VERSION ""

NS_ :

BS_:
BU_: ME SC01 BMS01 BMS PT
BO_ 113 BMS05_DriveLimits: 8 BMS05
 SG_ dchgCurrentLimit_BMS05 : 55|16@0+ (0.05,0) [0|3200] "A"  BMS
 SG_ regenCurrentLimit_BMS05 : 39|16@0+ (0.05,0) [0|3200] "A"  BMS
 SG_ minStringVLimit_BMS05 : 23|16@0+ (0.02,0) [0|1200] "V"  BMS
 SG_ maxStringVLimit_BMS05 : 7|16@0+ (0.02,0) [0|1200] "V"  BMS

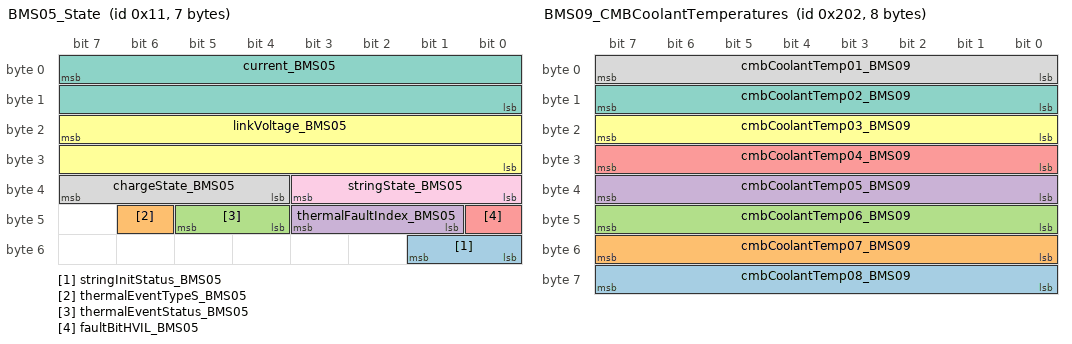
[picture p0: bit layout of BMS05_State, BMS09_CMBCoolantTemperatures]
BO_ 17 BMS05_State: 7 BMS05
 SG_ stringInitStatus_BMS05 : 49|2@0+ (1,0) [0|3] ""  BMS
 SG_ thermalEventTypeS_BMS05 : 46|1@0+ (1,0) [0|1] ""  BMS
 SG_ thermalEventStatus_BMS05 : 45|2@0+ (1,0) [0|2550] ""  BMS
 SG_ thermalFaultIndex_BMS05 : 43|3@0+ (1,0) [0|7] ""  BMS
 SG_ faultBitHVIL_BMS05 : 40|1@0+ (1,0) [0|1] ""  BMS
 SG_ linkVoltage_BMS05 : 23|16@0+ (0.02,0) [0|1200] "V"  BMS
 SG_ current_BMS05 : 7|16@0+ (0.1,-3200) [-3200|3353.5] "A"  BMS
 SG_ chargeState_BMS05 : 39|4@0+ (1,0) [0|15] ""  BMS
 SG_ stringState_BMS05 : 35|4@0+ (1,0) [0|0] ""  BMS

BO_ 402 BMS09_SlowDataMpex: 8 BMS09
 SG_ SW_VersionBL_BMS09 m4 : 15|32@0+ (1,0) [0|4294967295] ""  BMS
 SG_ SW_Version_BMS09 m3 : 15|32@0+ (1,0) [0|4294967295] ""  BMS
 SG_ PackSerialNumber_char20_BMS09 m2 : 55|8@0+ (1,0) [0|255] ""  BMS
 SG_ PackSerialNumber_char19_BMS09 m2 : 47|8@0+ (1,0) [0|255] ""  BMS
 SG_ PackSerialNumber_char18_BMS09 m2 : 39|8@0+ (1,0) [0|255] ""  BMS
 SG_ PackSerialNumber_char17_BMS09 m2 : 31|8@0+ (1,0) [0|255] ""  BMS
 SG_ PackSerialNumber_char16_BMS09 m2 : 23|8@0+ (1,0) [0|255] ""  BMS
 SG_ PackSerialNumber_char15_BMS09 m2 : 15|8@0+ (1,0) [0|255] ""  BMS
 SG_ PackSerialNumber_char14_BMS09 m1 : 63|8@0+ (1,0) [0|255] ""  BMS
 SG_ PackSerialNumber_char13_BMS09 m1 : 55|8@0+ (1,0) [0|255] ""  BMS
 SG_ PackSerialNumber_char12_BMS09 m1 : 47|8@0+ (1,0) [0|255] ""  BMS
 SG_ PackSerialNumber_char11_BMS09 m1 : 39|8@0+ (1,0) [0|255] ""  BMS
 SG_ PackSerialNumber_char10_BMS09 m1 : 31|8@0+ (1,0) [0|255] ""  BMS
 SG_ PackSerialNumber_char08_BMS09 m1 : 15|8@0+ (1,0) [0|255] ""  BMS
 SG_ PackSerialNumber_char09_BMS09 m1 : 23|8@0+ (1,0) [0|255] ""  BMS
 SG_ SlowDataMpx_BMS09 M : 7|8@0+ (1,0) [0|255] ""  BMS
 SG_ PackSerialNumber_char07_BMS09 m0 : 63|8@0+ (1,0) [0|255] ""  BMS
 SG_ PackSerialNumber_char06_BMS09 m0 : 55|8@0+ (1,0) [0|255] ""  BMS
 SG_ PackSerialNumber_char05_BMS09 m0 : 47|8@0+ (1,0) [0|255] ""  BMS
 SG_ PackSerialNumber_char04_BMS09 m0 : 39|8@0+ (1,0) [0|255] ""  BMS
 SG_ PackSerialNumber_char03_BMS09 m0 : 31|8@0+ (1,0) [0|255] ""  BMS
 SG_ PackSerialNumber_char02_BMS09 m0 : 23|8@0+ (1,0) [0|255] ""  BMS
 SG_ PackSerialNumber_char01_BMS09 m0 : 15|8@0+ (1,0) [0|255] ""  BMS

BO_ 530 BMS09_CoolantTemperatures: 8 BMS
 SG_ coolantOutletTemperature_BMS09 : 15|8@0+ (1,-40) [-40|215] "C"  BMS
 SG_ coolantInletTemperature_BMS09 : 7|8@0+ (1,-40) [-40|215] "C"  BMS

BO_ 514 BMS09_CMBCoolantTemperatures: 8 BMS
 SG_ cmbCoolantTemp08_BMS09 : 63|8@0+ (1,-40) [-40|200] "C"  BMS
 SG_ cmbCoolantTemp07_BMS09 : 55|8@0+ (1,-40) [-40|200] "C"  BMS
 SG_ cmbCoolantTemp06_BMS09 : 47|8@0+ (1,-40) [-40|200] "C"  BMS
 SG_ cmbCoolantTemp05_BMS09 : 39|8@0+ (1,-40) [-40|200] "C"  BMS
 SG_ cmbCoolantTemp04_BMS09 : 31|8@0+ (1,-40) [-40|200] "C"  BMS
 SG_ cmbCoolantTemp03_BMS09 : 23|8@0+ (1,-40) [-40|200] "C"  BMS
 SG_ cmbCoolantTemp02_BMS09 : 15|8@0+ (1,-40) [-40|200] "C"  BMS
 SG_ cmbCoolantTemp01_BMS09 : 7|8@0+ (1,-40) [-40|200] "C"  BMS

BO_ 386 BMS09_EnergyThroughput: 5 BMS09
 SG_ maxFluidPressureInlet_BMS09 : 39|8@0+ (10,0) [0|2550] "mbar"  BMS
 SG_ energyThroughput_KWh_BMS09 : 7|32@0+ (0.01,0) [0|42949672.95] "KWh"  BMS

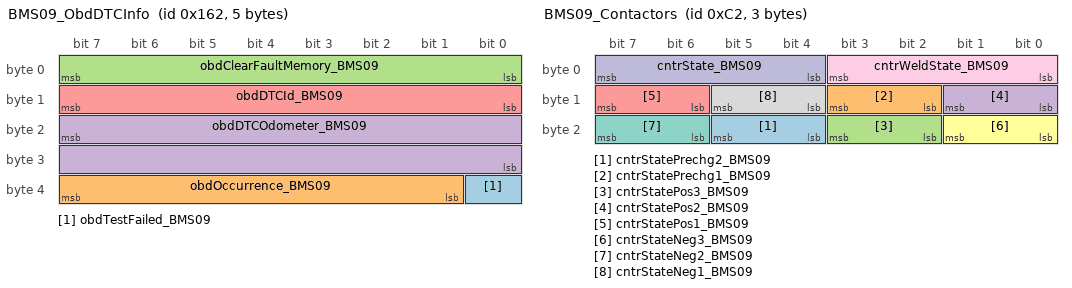
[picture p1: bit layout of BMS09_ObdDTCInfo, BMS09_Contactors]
BO_ 354 BMS09_ObdDTCInfo: 5 BMS09
 SG_ obdTestFailed_BMS09 : 32|1@0+ (1,0) [0|1] ""  BMS
 SG_ obdOccurrence_BMS09 : 39|7@0+ (1,0) [0|126] ""  BMS
 SG_ obdClearFaultMemory_BMS09 : 7|8@0+ (1,0) [0|1] ""  BMS
 SG_ obdDTCOdometer_BMS09 : 23|16@0+ (1,0) [0|65535] "km"  BMS
 SG_ obdDTCId_BMS09 : 15|8@0+ (1,0) [0|255] ""  BMS

BO_ 338 BMS09_SOCIndeces: 4 BMS09
 SG_ maxSOCIndex_BMS09 : 23|16@0+ (1,0) [0|65535] ""  BMS
 SG_ minSOCIndex_BMS09 : 7|16@0+ (1,0) [0|65535] ""  BMS

BO_ 322 BMS09_Charge: 8 BMS09
 SG_ cusDschrgEnrgyLifeTime_BMS09 : 55|16@0+ (0.1,0) [0|1310.7] "MWh"  BMS
 SG_ cusChrgEnrgyLifeTime_BMS09 : 39|16@0+ (0.1,0) [0|1310.7] "MWh"  BMS
 SG_ chargeEnergyAvailable_BMS09 : 7|16@0+ (0.01,0) [0|0] "kWh"  BMS

BO_ 210 BMS09_StringShutdown: 3 BMS09
 SG_ stringShutdownTarget_BMS09 : 19|4@0+ (1,0) [0|0] ""  BMS
 SG_ stringShutdownTimer_BMS09 : 7|16@0+ (1,0) [0|0] ""  BMS

BO_ 194 BMS09_Contactors: 3 BMS09
 SG_ cntrStatePrechg2_BMS09 : 21|2@0+ (1,0) [0|0] ""  BMS
 SG_ cntrStatePrechg1_BMS09 : 11|2@0+ (1,0) [0|0] ""  BMS
 SG_ cntrStatePos3_BMS09 : 19|2@0+ (1,0) [0|0] ""  BMS
 SG_ cntrStatePos2_BMS09 : 9|2@0+ (1,0) [0|0] ""  BMS
 SG_ cntrStatePos1_BMS09 : 15|2@0+ (1,0) [0|0] ""  BMS
 SG_ cntrStateNeg3_BMS09 : 17|2@0+ (1,0) [0|0] ""  BMS
 SG_ cntrStateNeg2_BMS09 : 23|2@0+ (1,0) [0|0] ""  BMS
 SG_ cntrStateNeg1_BMS09 : 13|2@0+ (1,0) [0|0] ""  BMS
 SG_ cntrWeldState_BMS09 : 3|4@0+ (1,0) [0|0] ""  BMS
 SG_ cntrState_BMS09 : 7|4@0+ (1,0) [0|0] ""  BMS

BO_ 162 BMS09_PowerPrediction: 8 BMS09
 SG_ regenPowerPredShrt_BMS09 : 39|16@0+ (0.01,0) [0|650] "kW"  BMS
 SG_ regenPowerPredLong_BMS09 : 55|16@0+ (0.01,0) [0|650] "kW"  BMS
 SG_ dchgPowerPredShrt_BMS09 : 7|16@0+ (0.01,0) [0|650] "kW"  BMS
 SG_ dchgPowerPredLong_BMS09 : 23|16@0+ (0.01,0) [0|650] "kW"  BMS

BO_ 178 BMS09_CellVLimits: 8 BMS09
 SG_ cusMaxCellVLimit_BMS09 : 23|16@0+ (0.0001,0) [0|6.5] "V"  BMS
 SG_ cusMinCellVLimit_BMS09 : 7|16@0+ (0.0001,0) [0|6.5] "V"  BMS

BO_ 146 BMS09_VoltagePrediction: 8 BMS09
 SG_ dchgVoltagePredShrt_BMS09 : 7|16@0+ (0.02,0) [0|1200] "V"  BMS
 SG_ dchgVoltagePredLong_BMS09 : 23|16@0+ (0.02,0) [0|1200] "V"  BMS
 SG_ regenVoltagePredShrt_BMS09 : 39|16@0+ (0.02,0) [0|1200] "V"  BMS
 SG_ regenVoltagePredLong_BMS09 : 55|16@0+ (0.02,0) [0|1200] "V"  BMS

BO_ 130 BMS09_CurrentPrediction: 8 BMS09
 SG_ regenCurrentPredShrt_BMS09 : 39|16@0+ (0.05,0) [0|3200] "A"  BMS
 SG_ regenCurrentPredLong_BMS09 : 55|16@0+ (0.05,0) [0|3200] "A"  BMS
 SG_ dchgCurrentPredShrt_BMS09 : 7|16@0+ (0.05,0) [0|3200] "A"  BMS
 SG_ dchgCurrentPredLong_BMS09 : 23|16@0+ (0.05,0) [0|3200] "A"  BMS

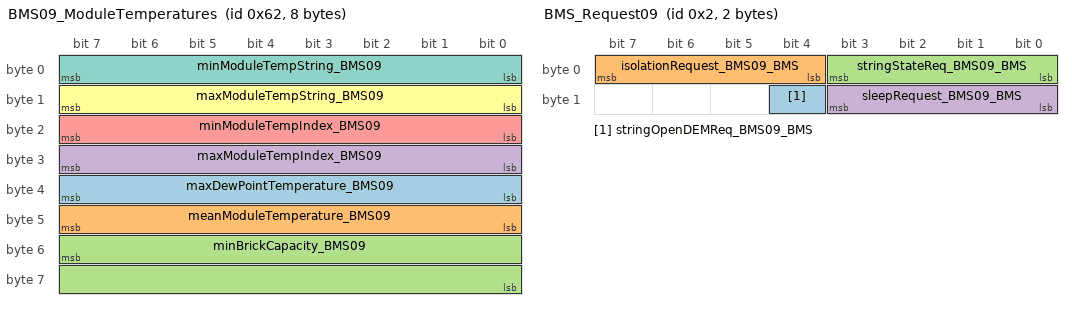
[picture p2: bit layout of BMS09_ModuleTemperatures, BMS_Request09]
BO_ 98 BMS09_ModuleTemperatures: 8 BMS09
 SG_ maxDewPointTemperature_BMS09 : 39|8@0+ (0.5,-40) [-40|87.5] "C"  BMS
 SG_ meanModuleTemperature_BMS09 : 47|8@0+ (0.5,-40) [-40|87.5] "C"  BMS
 SG_ minBrickCapacity_BMS09 : 55|16@0+ (20,0) [0|1310700] "As"  BMS
 SG_ maxModuleTempIndex_BMS09 : 31|8@0+ (1,0) [0|255] ""  BMS
 SG_ minModuleTempIndex_BMS09 : 23|8@0+ (1,0) [0|255] ""  BMS
 SG_ maxModuleTempString_BMS09 : 15|8@0+ (0.5,-40) [-40|87.5] "C"  BMS
 SG_ minModuleTempString_BMS09 : 7|8@0+ (0.5,-40) [-40|87.5] "C"  BMS

BO_ 34 BMS09_StringVoltageCharge: 8 BMS09
 SG_ brickOpenCircuitV_BMS09 : 55|16@0+ (0.0001,0) [0|6.5] "V"  BMS
 SG_ meanSOC_BMS09 : 39|16@0+ (0.01,0) [0|100] "PCT"  BMS
 SG_ stringVoltage_BMS09 : 7|16@0+ (0.02,0) [0|1200] "V"  BMS
 SG_ chargerCurrentLimit_BMS09 : 23|16@0+ (0.05,0) [0|3200] "A"  BMS

BO_ 2 BMS_Request09: 2 BMS
 SG_ stringOpenDEMReq_BMS09_BMS : 12|1@0+ (1,0) [0|0] ""  BMS
 SG_ isolationRequest_BMS09_BMS : 7|4@0+ (1,0) [0|0] ""  BMS
 SG_ stringStateReq_BMS09_BMS : 3|4@0+ (1,0) [0|0] ""  BMS
 SG_ sleepRequest_BMS09_BMS : 11|4@0+ (1,0) [0|0] ""  BMS

BO_ 82 BMS09_BrickVoltages: 8 BMS09
 SG_ maxBrickVoltageIndex_BMS09 : 55|16@0+ (1,0) [0|65535] ""  BMS
 SG_ minBrickVoltageIndex_BMS09 : 39|16@0+ (1,0) [0|65535] ""  BMS
 SG_ minBrickVoltage_BMS09 : 7|16@0+ (0.0001,0) [0|6.5] "V"  BMS
 SG_ maxBrickVoltage_BMS09 : 23|16@0+ (0.0001,0) [0|6.5] "V"  BMS

BO_ 50 BMS09_IsolationSOC: 8 BMS09
 SG_ maxSOC_BMS09 : 55|16@0+ (0.01,0) [0|100] "PCT"  BMS
 SG_ minSOC_BMS09 : 39|16@0+ (0.01,0) [0|100] "PCT"  BMS
 SG_ isolationResInternal_BMS09 : 23|16@0+ (2,0) [0|130000] "kOhm"  BMS
 SG_ isolationResExternal_BMS09 : 7|16@0+ (2,0) [0|130000] "kOhm"  BMS

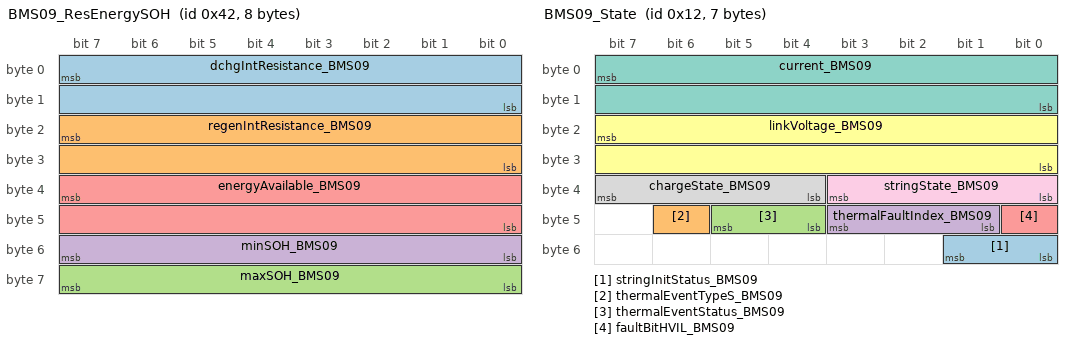
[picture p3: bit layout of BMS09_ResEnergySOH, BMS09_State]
BO_ 66 BMS09_ResEnergySOH: 8 BMS09
 SG_ dchgIntResistance_BMS09 : 7|16@0+ (0.05,0) [0|3276.75] "mOhm"  BMS
 SG_ regenIntResistance_BMS09 : 23|16@0+ (0.05,0) [0|3276.75] "mOhm"  BMS
 SG_ maxSOH_BMS09 : 63|8@0+ (0.5,0) [0|120] "PCT"  BMS
 SG_ minSOH_BMS09 : 55|8@0+ (0.5,0) [0|120] "PCT"  BMS
 SG_ energyAvailable_BMS09 : 39|16@0+ (0.01,0) [0|650] "kWh"  BMS

BO_ 114 BMS09_DriveLimits: 8 BMS09
 SG_ dchgCurrentLimit_BMS09 : 55|16@0+ (0.05,0) [0|3200] "A"  BMS
 SG_ regenCurrentLimit_BMS09 : 39|16@0+ (0.05,0) [0|3200] "A"  BMS
 SG_ minStringVLimit_BMS09 : 23|16@0+ (0.02,0) [0|1200] "V"  BMS
 SG_ maxStringVLimit_BMS09 : 7|16@0+ (0.02,0) [0|1200] "V"  BMS

BO_ 18 BMS09_State: 7 BMS09
 SG_ stringInitStatus_BMS09 : 49|2@0+ (1,0) [0|3] ""  BMS
 SG_ thermalEventTypeS_BMS09 : 46|1@0+ (1,0) [0|1] ""  BMS
 SG_ thermalEventStatus_BMS09 : 45|2@0+ (1,0) [0|2550] ""  BMS
 SG_ thermalFaultIndex_BMS09 : 43|3@0+ (1,0) [0|7] ""  BMS
 SG_ faultBitHVIL_BMS09 : 40|1@0+ (1,0) [0|1] ""  BMS
 SG_ linkVoltage_BMS09 : 23|16@0+ (0.02,0) [0|1200] "V"  BMS
 SG_ current_BMS09 : 7|16@0+ (0.1,-3200) [-3200|3353.5] "A"  BMS
 SG_ chargeState_BMS09 : 39|4@0+ (1,0) [0|15] ""  BMS
 SG_ stringState_BMS09 : 35|4@0+ (1,0) [0|0] ""  BMS

BO_ 403 BMS13_SlowDataMpex: 8 BMS13
 SG_ SW_VersionBL_BMS13 m4 : 15|32@0+ (1,0) [0|4294967295] ""  BMS
 SG_ SW_Version_BMS13 m3 : 15|32@0+ (1,0) [0|4294967295] ""  BMS
 SG_ PackSerialNumber_char20_BMS13 m2 : 55|8@0+ (1,0) [0|255] ""  BMS
 SG_ PackSerialNumber_char19_BMS13 m2 : 47|8@0+ (1,0) [0|255] ""  BMS
 SG_ PackSerialNumber_char18_BMS13 m2 : 39|8@0+ (1,0) [0|255] ""  BMS
 SG_ PackSerialNumber_char17_BMS13 m2 : 31|8@0+ (1,0) [0|255] ""  BMS
 SG_ PackSerialNumber_char16_BMS13 m2 : 23|8@0+ (1,0) [0|255] ""  BMS
 SG_ PackSerialNumber_char15_BMS13 m2 : 15|8@0+ (1,0) [0|255] ""  BMS
 SG_ PackSerialNumber_char14_BMS13 m1 : 63|8@0+ (1,0) [0|255] ""  BMS
 SG_ PackSerialNumber_char13_BMS13 m1 : 55|8@0+ (1,0) [0|255] ""  BMS
 SG_ PackSerialNumber_char12_BMS13 m1 : 47|8@0+ (1,0) [0|255] ""  BMS
 SG_ PackSerialNumber_char11_BMS13 m1 : 39|8@0+ (1,0) [0|255] ""  BMS
 SG_ PackSerialNumber_char10_BMS13 m1 : 31|8@0+ (1,0) [0|255] ""  BMS
 SG_ PackSerialNumber_char08_BMS13 m1 : 15|8@0+ (1,0) [0|255] ""  BMS
 SG_ PackSerialNumber_char09_BMS13 m1 : 23|8@0+ (1,0) [0|255] ""  BMS
 SG_ SlowDataMpx_BMS13 M : 7|8@0+ (1,0) [0|255] ""  BMS
 SG_ PackSerialNumber_char07_BMS13 m0 : 63|8@0+ (1,0) [0|255] ""  BMS
 SG_ PackSerialNumber_char06_BMS13 m0 : 55|8@0+ (1,0) [0|255] ""  BMS
 SG_ PackSerialNumber_char05_BMS13 m0 : 47|8@0+ (1,0) [0|255] ""  BMS
 SG_ PackSerialNumber_char04_BMS13 m0 : 39|8@0+ (1,0) [0|255] ""  BMS
 SG_ PackSerialNumber_char03_BMS13 m0 : 31|8@0+ (1,0) [0|255] ""  BMS
 SG_ PackSerialNumber_char02_BMS13 m0 : 23|8@0+ (1,0) [0|255] ""  BMS
 SG_ PackSerialNumber_char01_BMS13 m0 : 15|8@0+ (1,0) [0|255] ""  BMS

BO_ 531 BMS13_CoolantTemperatures: 8 BMS
 SG_ coolantOutletTemperature_BMS13 : 15|8@0+ (1,-40) [-40|215] "C"  BMS
 SG_ coolantInletTemperature_BMS13 : 7|8@0+ (1,-40) [-40|215] "C"  BMS

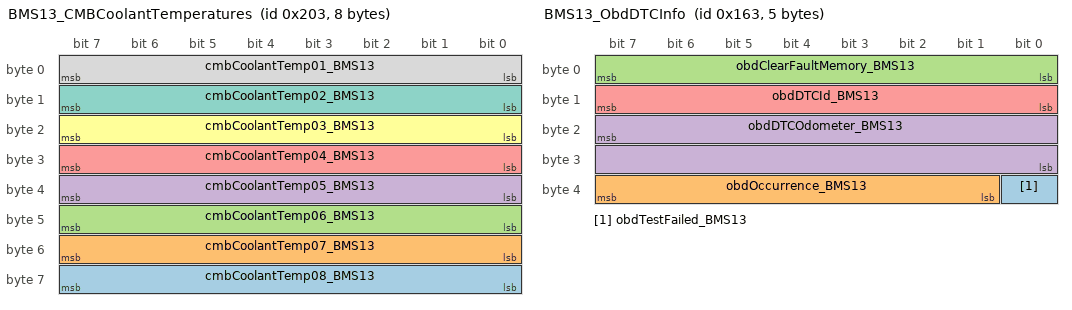
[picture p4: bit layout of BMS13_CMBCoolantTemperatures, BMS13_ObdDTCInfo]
BO_ 515 BMS13_CMBCoolantTemperatures: 8 BMS
 SG_ cmbCoolantTemp08_BMS13 : 63|8@0+ (1,-40) [-40|200] "C"  BMS
 SG_ cmbCoolantTemp07_BMS13 : 55|8@0+ (1,-40) [-40|200] "C"  BMS
 SG_ cmbCoolantTemp06_BMS13 : 47|8@0+ (1,-40) [-40|200] "C"  BMS
 SG_ cmbCoolantTemp05_BMS13 : 39|8@0+ (1,-40) [-40|200] "C"  BMS
 SG_ cmbCoolantTemp04_BMS13 : 31|8@0+ (1,-40) [-40|200] "C"  BMS
 SG_ cmbCoolantTemp03_BMS13 : 23|8@0+ (1,-40) [-40|200] "C"  BMS
 SG_ cmbCoolantTemp02_BMS13 : 15|8@0+ (1,-40) [-40|200] "C"  BMS
 SG_ cmbCoolantTemp01_BMS13 : 7|8@0+ (1,-40) [-40|200] "C"  BMS

BO_ 387 BMS13_EnergyThroughput: 5 BMS13
 SG_ maxFluidPressureInlet_BMS13 : 39|8@0+ (10,0) [0|2550] "mbar"  BMS
 SG_ energyThroughput_KWh_BMS13 : 7|32@0+ (0.01,0) [0|42949672.95] "KWh"  BMS

BO_ 355 BMS13_ObdDTCInfo: 5 BMS13
 SG_ obdTestFailed_BMS13 : 32|1@0+ (1,0) [0|1] ""  BMS
 SG_ obdOccurrence_BMS13 : 39|7@0+ (1,0) [0|126] ""  BMS
 SG_ obdClearFaultMemory_BMS13 : 7|8@0+ (1,0) [0|1] ""  BMS
 SG_ obdDTCOdometer_BMS13 : 23|16@0+ (1,0) [0|65535] "km"  BMS
 SG_ obdDTCId_BMS13 : 15|8@0+ (1,0) [0|255] ""  BMS

BO_ 339 BMS13_SOCIndeces: 4 BMS13
 SG_ maxSOCIndex_BMS13 : 23|16@0+ (1,0) [0|65535] ""  BMS
 SG_ minSOCIndex_BMS13 : 7|16@0+ (1,0) [0|65535] ""  BMS

BO_ 323 BMS13_Charge: 8 BMS13
 SG_ cusDschrgEnrgyLifeTime_BMS13 : 55|16@0+ (0.1,0) [0|1310.7] "MWh"  BMS
 SG_ cusChrgEnrgyLifeTime_BMS13 : 39|16@0+ (0.1,0) [0|1310.7] "MWh"  BMS
 SG_ chargeEnergyAvailable_BMS13 : 7|16@0+ (0.01,0) [0|0] "kWh"  BMS

BO_ 211 BMS13_StringShutdown: 3 BMS13
 SG_ stringShutdownTarget_BMS13 : 19|4@0+ (1,0) [0|0] ""  BMS
 SG_ stringShutdownTimer_BMS13 : 7|16@0+ (1,0) [0|0] ""  BMS

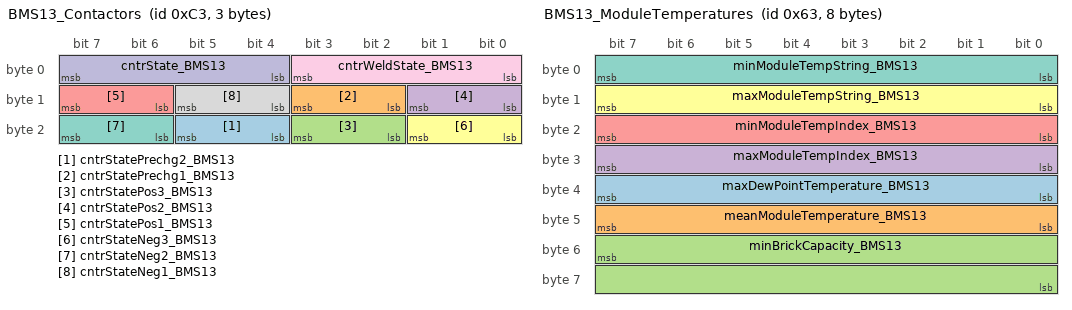
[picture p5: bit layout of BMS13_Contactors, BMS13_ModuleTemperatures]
BO_ 195 BMS13_Contactors: 3 BMS13
 SG_ cntrStatePrechg2_BMS13 : 21|2@0+ (1,0) [0|0] ""  BMS
 SG_ cntrStatePrechg1_BMS13 : 11|2@0+ (1,0) [0|0] ""  BMS
 SG_ cntrStatePos3_BMS13 : 19|2@0+ (1,0) [0|0] ""  BMS
 SG_ cntrStatePos2_BMS13 : 9|2@0+ (1,0) [0|0] ""  BMS
 SG_ cntrStatePos1_BMS13 : 15|2@0+ (1,0) [0|0] ""  BMS
 SG_ cntrStateNeg3_BMS13 : 17|2@0+ (1,0) [0|0] ""  BMS
 SG_ cntrStateNeg2_BMS13 : 23|2@0+ (1,0) [0|0] ""  BMS
 SG_ cntrStateNeg1_BMS13 : 13|2@0+ (1,0) [0|0] ""  BMS
 SG_ cntrWeldState_BMS13 : 3|4@0+ (1,0) [0|0] ""  BMS
 SG_ cntrState_BMS13 : 7|4@0+ (1,0) [0|0] ""  BMS

BO_ 163 BMS13_PowerPrediction: 8 BMS13
 SG_ regenPowerPredShrt_BMS13 : 39|16@0+ (0.01,0) [0|650] "kW"  BMS
 SG_ regenPowerPredLong_BMS13 : 55|16@0+ (0.01,0) [0|650] "kW"  BMS
 SG_ dchgPowerPredShrt_BMS13 : 7|16@0+ (0.01,0) [0|650] "kW"  BMS
 SG_ dchgPowerPredLong_BMS13 : 23|16@0+ (0.01,0) [0|650] "kW"  BMS

BO_ 179 BMS13_CellVLimits: 8 BMS13
 SG_ cusMaxCellVLimit_BMS13 : 23|16@0+ (0.0001,0) [0|6.5] "V"  BMS
 SG_ cusMinCellVLimit_BMS13 : 7|16@0+ (0.0001,0) [0|6.5] "V"  BMS

BO_ 147 BMS13_VoltagePrediction: 8 BMS13
 SG_ dchgVoltagePredShrt_BMS13 : 7|16@0+ (0.02,0) [0|1200] "V"  BMS
 SG_ dchgVoltagePredLong_BMS13 : 23|16@0+ (0.02,0) [0|1200] "V"  BMS
 SG_ regenVoltagePredShrt_BMS13 : 39|16@0+ (0.02,0) [0|1200] "V"  BMS
 SG_ regenVoltagePredLong_BMS13 : 55|16@0+ (0.02,0) [0|1200] "V"  BMS

BO_ 131 BMS13_CurrentPrediction: 8 BMS13
 SG_ regenCurrentPredShrt_BMS13 : 39|16@0+ (0.05,0) [0|3200] "A"  BMS
 SG_ regenCurrentPredLong_BMS13 : 55|16@0+ (0.05,0) [0|3200] "A"  BMS
 SG_ dchgCurrentPredShrt_BMS13 : 7|16@0+ (0.05,0) [0|3200] "A"  BMS
 SG_ dchgCurrentPredLong_BMS13 : 23|16@0+ (0.05,0) [0|3200] "A"  BMS

BO_ 99 BMS13_ModuleTemperatures: 8 BMS13
 SG_ maxDewPointTemperature_BMS13 : 39|8@0+ (0.5,-40) [-40|87.5] "C"  BMS
 SG_ meanModuleTemperature_BMS13 : 47|8@0+ (0.5,-40) [-40|87.5] "C"  BMS
 SG_ minBrickCapacity_BMS13 : 55|16@0+ (20,0) [0|1310700] "As"  BMS
 SG_ maxModuleTempIndex_BMS13 : 31|8@0+ (1,0) [0|255] ""  BMS
 SG_ minModuleTempIndex_BMS13 : 23|8@0+ (1,0) [0|255] ""  BMS
 SG_ maxModuleTempString_BMS13 : 15|8@0+ (0.5,-40) [-40|87.5] "C"  BMS
 SG_ minModuleTempString_BMS13 : 7|8@0+ (0.5,-40) [-40|87.5] "C"  BMS

BO_ 35 BMS13_StringVoltageCharge: 8 BMS13
 SG_ brickOpenCircuitV_BMS13 : 55|16@0+ (0.0001,0) [0|6.5] "V"  BMS
 SG_ meanSOC_BMS13 : 39|16@0+ (0.01,0) [0|100] "PCT"  BMS
 SG_ stringVoltage_BMS13 : 7|16@0+ (0.02,0) [0|1200] "V"  BMS
 SG_ chargerCurrentLimit_BMS13 : 23|16@0+ (0.05,0) [0|3200] "A"  BMS

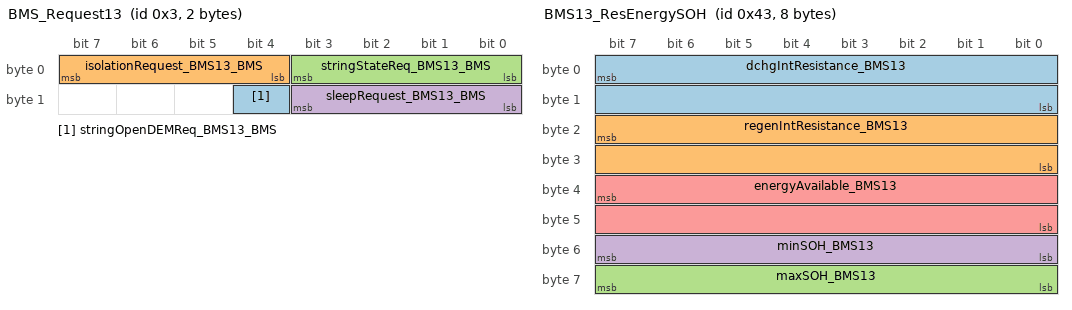
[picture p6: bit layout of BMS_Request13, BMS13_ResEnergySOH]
BO_ 3 BMS_Request13: 2 BMS
 SG_ stringOpenDEMReq_BMS13_BMS : 12|1@0+ (1,0) [0|0] ""  BMS
 SG_ isolationRequest_BMS13_BMS : 7|4@0+ (1,0) [0|0] ""  BMS
 SG_ stringStateReq_BMS13_BMS : 3|4@0+ (1,0) [0|0] ""  BMS
 SG_ sleepRequest_BMS13_BMS : 11|4@0+ (1,0) [0|0] ""  BMS

BO_ 83 BMS13_BrickVoltages: 8 BMS13
 SG_ maxBrickVoltageIndex_BMS13 : 55|16@0+ (1,0) [0|65535] ""  BMS
 SG_ minBrickVoltageIndex_BMS13 : 39|16@0+ (1,0) [0|65535] ""  BMS
 SG_ minBrickVoltage_BMS13 : 7|16@0+ (0.0001,0) [0|6.5] "V"  BMS
 SG_ maxBrickVoltage_BMS13 : 23|16@0+ (0.0001,0) [0|6.5] "V"  BMS

BO_ 51 BMS13_IsolationSOC: 8 BMS13
 SG_ maxSOC_BMS13 : 55|16@0+ (0.01,0) [0|100] "PCT"  BMS
 SG_ minSOC_BMS13 : 39|16@0+ (0.01,0) [0|100] "PCT"  BMS
 SG_ isolationResInternal_BMS13 : 23|16@0+ (2,0) [0|130000] "kOhm"  BMS
 SG_ isolationResExternal_BMS13 : 7|16@0+ (2,0) [0|130000] "kOhm"  BMS

BO_ 67 BMS13_ResEnergySOH: 8 BMS13
 SG_ dchgIntResistance_BMS13 : 7|16@0+ (0.05,0) [0|3276.75] "mOhm"  BMS
 SG_ regenIntResistance_BMS13 : 23|16@0+ (0.05,0) [0|3276.75] "mOhm"  BMS
 SG_ maxSOH_BMS13 : 63|8@0+ (0.5,0) [0|120] "PCT"  BMS
 SG_ minSOH_BMS13 : 55|8@0+ (0.5,0) [0|120] "PCT"  BMS
 SG_ energyAvailable_BMS13 : 39|16@0+ (0.01,0) [0|650] "kWh"  BMS

BO_ 115 BMS13_DriveLimits: 8 BMS13
 SG_ dchgCurrentLimit_BMS13 : 55|16@0+ (0.05,0) [0|3200] "A"  BMS
 SG_ regenCurrentLimit_BMS13 : 39|16@0+ (0.05,0) [0|3200] "A"  BMS
 SG_ minStringVLimit_BMS13 : 23|16@0+ (0.02,0) [0|1200] "V"  BMS
 SG_ maxStringVLimit_BMS13 : 7|16@0+ (0.02,0) [0|1200] "V"  BMS

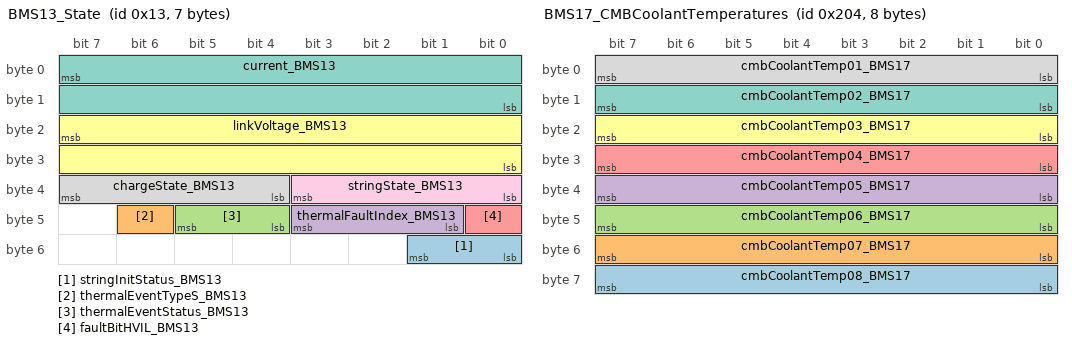
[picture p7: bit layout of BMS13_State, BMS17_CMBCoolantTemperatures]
BO_ 19 BMS13_State: 7 BMS13
 SG_ stringInitStatus_BMS13 : 49|2@0+ (1,0) [0|3] ""  BMS
 SG_ thermalEventTypeS_BMS13 : 46|1@0+ (1,0) [0|1] ""  BMS
 SG_ thermalEventStatus_BMS13 : 45|2@0+ (1,0) [0|2550] ""  BMS
 SG_ thermalFaultIndex_BMS13 : 43|3@0+ (1,0) [0|7] ""  BMS
 SG_ faultBitHVIL_BMS13 : 40|1@0+ (1,0) [0|1] ""  BMS
 SG_ linkVoltage_BMS13 : 23|16@0+ (0.02,0) [0|1200] "V"  BMS
 SG_ current_BMS13 : 7|16@0+ (0.1,-3200) [-3200|3353.5] "A"  BMS
 SG_ chargeState_BMS13 : 39|4@0+ (1,0) [0|15] ""  BMS
 SG_ stringState_BMS13 : 35|4@0+ (1,0) [0|0] ""  BMS

BO_ 404 BMS17_SlowDataMpex: 8 BMS17
 SG_ SW_VersionBL_BMS17 m4 : 15|32@0+ (1,0) [0|4294967295] ""  BMS
 SG_ SW_Version_BMS17 m3 : 15|32@0+ (1,0) [0|4294967295] ""  BMS
 SG_ PackSerialNumber_char20_BMS17 m2 : 55|8@0+ (1,0) [0|255] ""  BMS
 SG_ PackSerialNumber_char19_BMS17 m2 : 47|8@0+ (1,0) [0|255] ""  BMS
 SG_ PackSerialNumber_char18_BMS17 m2 : 39|8@0+ (1,0) [0|255] ""  BMS
 SG_ PackSerialNumber_char17_BMS17 m2 : 31|8@0+ (1,0) [0|255] ""  BMS
 SG_ PackSerialNumber_char16_BMS17 m2 : 23|8@0+ (1,0) [0|255] ""  BMS
 SG_ PackSerialNumber_char15_BMS17 m2 : 15|8@0+ (1,0) [0|255] ""  BMS
 SG_ PackSerialNumber_char14_BMS17 m1 : 63|8@0+ (1,0) [0|255] ""  BMS
 SG_ PackSerialNumber_char13_BMS17 m1 : 55|8@0+ (1,0) [0|255] ""  BMS
 SG_ PackSerialNumber_char12_BMS17 m1 : 47|8@0+ (1,0) [0|255] ""  BMS
 SG_ PackSerialNumber_char11_BMS17 m1 : 39|8@0+ (1,0) [0|255] ""  BMS
 SG_ PackSerialNumber_char10_BMS17 m1 : 31|8@0+ (1,0) [0|255] ""  BMS
 SG_ PackSerialNumber_char08_BMS17 m1 : 15|8@0+ (1,0) [0|255] ""  BMS
 SG_ PackSerialNumber_char09_BMS17 m1 : 23|8@0+ (1,0) [0|255] ""  BMS
 SG_ SlowDataMpx_BMS17 M : 7|8@0+ (1,0) [0|255] ""  BMS
 SG_ PackSerialNumber_char07_BMS17 m0 : 63|8@0+ (1,0) [0|255] ""  BMS
 SG_ PackSerialNumber_char06_BMS17 m0 : 55|8@0+ (1,0) [0|255] ""  BMS
 SG_ PackSerialNumber_char05_BMS17 m0 : 47|8@0+ (1,0) [0|255] ""  BMS
 SG_ PackSerialNumber_char04_BMS17 m0 : 39|8@0+ (1,0) [0|255] ""  BMS
 SG_ PackSerialNumber_char03_BMS17 m0 : 31|8@0+ (1,0) [0|255] ""  BMS
 SG_ PackSerialNumber_char02_BMS17 m0 : 23|8@0+ (1,0) [0|255] ""  BMS
 SG_ PackSerialNumber_char01_BMS17 m0 : 15|8@0+ (1,0) [0|255] ""  BMS

BO_ 532 BMS17_CoolantTemperatures: 8 BMS
 SG_ coolantOutletTemperature_BMS17 : 15|8@0+ (1,-40) [-40|215] "C"  BMS
 SG_ coolantInletTemperature_BMS17 : 7|8@0+ (1,-40) [-40|215] "C"  BMS

BO_ 516 BMS17_CMBCoolantTemperatures: 8 BMS
 SG_ cmbCoolantTemp08_BMS17 : 63|8@0+ (1,-40) [-40|200] "C"  BMS
 SG_ cmbCoolantTemp07_BMS17 : 55|8@0+ (1,-40) [-40|200] "C"  BMS
 SG_ cmbCoolantTemp06_BMS17 : 47|8@0+ (1,-40) [-40|200] "C"  BMS
 SG_ cmbCoolantTemp05_BMS17 : 39|8@0+ (1,-40) [-40|200] "C"  BMS
 SG_ cmbCoolantTemp04_BMS17 : 31|8@0+ (1,-40) [-40|200] "C"  BMS
 SG_ cmbCoolantTemp03_BMS17 : 23|8@0+ (1,-40) [-40|200] "C"  BMS
 SG_ cmbCoolantTemp02_BMS17 : 15|8@0+ (1,-40) [-40|200] "C"  BMS
 SG_ cmbCoolantTemp01_BMS17 : 7|8@0+ (1,-40) [-40|200] "C"  BMS

BO_ 388 BMS17_EnergyThroughput: 5 BMS17
 SG_ maxFluidPressureInlet_BMS17 : 39|8@0+ (10,0) [0|2550] "mbar"  BMS
 SG_ energyThroughput_KWh_BMS17 : 7|32@0+ (0.01,0) [0|42949672.95] "KWh"  BMS

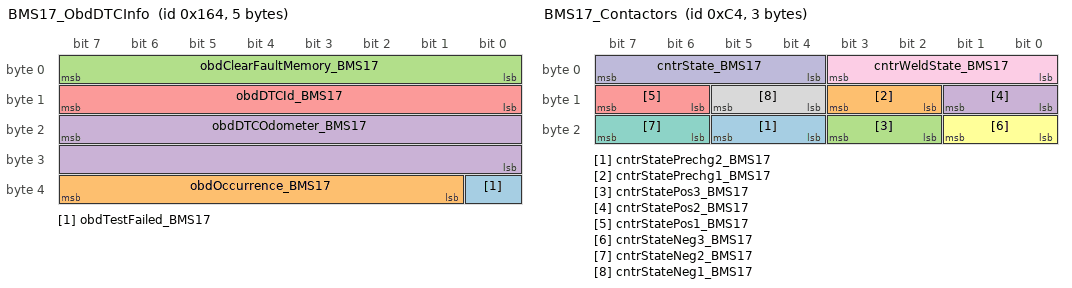
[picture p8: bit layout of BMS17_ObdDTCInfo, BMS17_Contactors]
BO_ 356 BMS17_ObdDTCInfo: 5 BMS17
 SG_ obdTestFailed_BMS17 : 32|1@0+ (1,0) [0|1] ""  BMS
 SG_ obdOccurrence_BMS17 : 39|7@0+ (1,0) [0|126] ""  BMS
 SG_ obdClearFaultMemory_BMS17 : 7|8@0+ (1,0) [0|1] ""  BMS
 SG_ obdDTCOdometer_BMS17 : 23|16@0+ (1,0) [0|65535] "km"  BMS
 SG_ obdDTCId_BMS17 : 15|8@0+ (1,0) [0|255] ""  BMS

BO_ 340 BMS17_SOCIndeces: 4 BMS17
 SG_ maxSOCIndex_BMS17 : 23|16@0+ (1,0) [0|65535] ""  BMS
 SG_ minSOCIndex_BMS17 : 7|16@0+ (1,0) [0|65535] ""  BMS

BO_ 324 BMS17_Charge: 8 BMS17
 SG_ cusDschrgEnrgyLifeTime_BMS17 : 55|16@0+ (0.1,0) [0|1310.7] "MWh"  BMS
 SG_ cusChrgEnrgyLifeTime_BMS17 : 39|16@0+ (0.1,0) [0|1310.7] "MWh"  BMS
 SG_ chargeEnergyAvailable_BMS17 : 7|16@0+ (0.01,0) [0|0] "kWh"  BMS

BO_ 212 BMS17_StringShutdown: 3 BMS17
 SG_ stringShutdownTarget_BMS17 : 19|4@0+ (1,0) [0|0] ""  BMS
 SG_ stringShutdownTimer_BMS17 : 7|16@0+ (1,0) [0|0] ""  BMS

BO_ 196 BMS17_Contactors: 3 BMS17
 SG_ cntrStatePrechg2_BMS17 : 21|2@0+ (1,0) [0|0] ""  BMS
 SG_ cntrStatePrechg1_BMS17 : 11|2@0+ (1,0) [0|0] ""  BMS
 SG_ cntrStatePos3_BMS17 : 19|2@0+ (1,0) [0|0] ""  BMS
 SG_ cntrStatePos2_BMS17 : 9|2@0+ (1,0) [0|0] ""  BMS
 SG_ cntrStatePos1_BMS17 : 15|2@0+ (1,0) [0|0] ""  BMS
 SG_ cntrStateNeg3_BMS17 : 17|2@0+ (1,0) [0|0] ""  BMS
 SG_ cntrStateNeg2_BMS17 : 23|2@0+ (1,0) [0|0] ""  BMS
 SG_ cntrStateNeg1_BMS17 : 13|2@0+ (1,0) [0|0] ""  BMS
 SG_ cntrWeldState_BMS17 : 3|4@0+ (1,0) [0|0] ""  BMS
 SG_ cntrState_BMS17 : 7|4@0+ (1,0) [0|0] ""  BMS

BO_ 164 BMS17_PowerPrediction: 8 BMS17
 SG_ regenPowerPredShrt_BMS17 : 39|16@0+ (0.01,0) [0|650] "kW"  BMS
 SG_ regenPowerPredLong_BMS17 : 55|16@0+ (0.01,0) [0|650] "kW"  BMS
 SG_ dchgPowerPredShrt_BMS17 : 7|16@0+ (0.01,0) [0|650] "kW"  BMS
 SG_ dchgPowerPredLong_BMS17 : 23|16@0+ (0.01,0) [0|650] "kW"  BMS

BO_ 180 BMS17_CellVLimits: 8 BMS17
 SG_ cusMaxCellVLimit_BMS17 : 23|16@0+ (0.0001,0) [0|6.5] "V"  BMS
 SG_ cusMinCellVLimit_BMS17 : 7|16@0+ (0.0001,0) [0|6.5] "V"  BMS

BO_ 148 BMS17_VoltagePrediction: 8 BMS17
 SG_ dchgVoltagePredShrt_BMS17 : 7|16@0+ (0.02,0) [0|1200] "V"  BMS
 SG_ dchgVoltagePredLong_BMS17 : 23|16@0+ (0.02,0) [0|1200] "V"  BMS
 SG_ regenVoltagePredShrt_BMS17 : 39|16@0+ (0.02,0) [0|1200] "V"  BMS
 SG_ regenVoltagePredLong_BMS17 : 55|16@0+ (0.02,0) [0|1200] "V"  BMS

BO_ 132 BMS17_CurrentPrediction: 8 BMS17
 SG_ regenCurrentPredShrt_BMS17 : 39|16@0+ (0.05,0) [0|3200] "A"  BMS
 SG_ regenCurrentPredLong_BMS17 : 55|16@0+ (0.05,0) [0|3200] "A"  BMS
 SG_ dchgCurrentPredShrt_BMS17 : 7|16@0+ (0.05,0) [0|3200] "A"  BMS
 SG_ dchgCurrentPredLong_BMS17 : 23|16@0+ (0.05,0) [0|3200] "A"  BMS

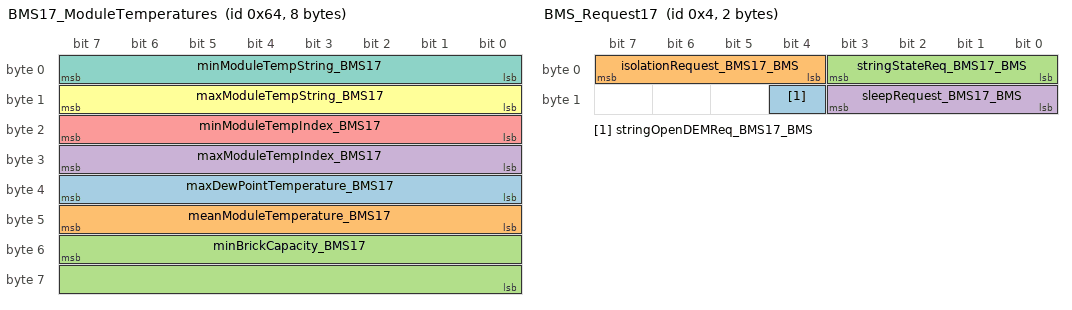
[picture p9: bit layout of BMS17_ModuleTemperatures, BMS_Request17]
BO_ 100 BMS17_ModuleTemperatures: 8 BMS17
 SG_ maxDewPointTemperature_BMS17 : 39|8@0+ (0.5,-40) [-40|87.5] "C"  BMS
 SG_ meanModuleTemperature_BMS17 : 47|8@0+ (0.5,-40) [-40|87.5] "C"  BMS
 SG_ minBrickCapacity_BMS17 : 55|16@0+ (20,0) [0|1310700] "As"  BMS
 SG_ maxModuleTempIndex_BMS17 : 31|8@0+ (1,0) [0|255] ""  BMS
 SG_ minModuleTempIndex_BMS17 : 23|8@0+ (1,0) [0|255] ""  BMS
 SG_ maxModuleTempString_BMS17 : 15|8@0+ (0.5,-40) [-40|87.5] "C"  BMS
 SG_ minModuleTempString_BMS17 : 7|8@0+ (0.5,-40) [-40|87.5] "C"  BMS

BO_ 36 BMS17_StringVoltageCharge: 8 BMS17
 SG_ brickOpenCircuitV_BMS17 : 55|16@0+ (0.0001,0) [0|6.5] "V"  BMS
 SG_ meanSOC_BMS17 : 39|16@0+ (0.01,0) [0|100] "PCT"  BMS
 SG_ stringVoltage_BMS17 : 7|16@0+ (0.02,0) [0|1200] "V"  BMS
 SG_ chargerCurrentLimit_BMS17 : 23|16@0+ (0.05,0) [0|3200] "A"  BMS

BO_ 4 BMS_Request17: 2 BMS
 SG_ stringOpenDEMReq_BMS17_BMS : 12|1@0+ (1,0) [0|0] ""  BMS
 SG_ isolationRequest_BMS17_BMS : 7|4@0+ (1,0) [0|0] ""  BMS
 SG_ stringStateReq_BMS17_BMS : 3|4@0+ (1,0) [0|0] ""  BMS
 SG_ sleepRequest_BMS17_BMS : 11|4@0+ (1,0) [0|0] ""  BMS

BO_ 84 BMS17_BrickVoltages: 8 BMS17
 SG_ maxBrickVoltageIndex_BMS17 : 55|16@0+ (1,0) [0|65535] ""  BMS
 SG_ minBrickVoltageIndex_BMS17 : 39|16@0+ (1,0) [0|65535] ""  BMS
 SG_ minBrickVoltage_BMS17 : 7|16@0+ (0.0001,0) [0|6.5] "V"  BMS
 SG_ maxBrickVoltage_BMS17 : 23|16@0+ (0.0001,0) [0|6.5] "V"  BMS

BO_ 52 BMS17_IsolationSOC: 8 BMS17
 SG_ maxSOC_BMS17 : 55|16@0+ (0.01,0) [0|100] "PCT"  BMS
 SG_ minSOC_BMS17 : 39|16@0+ (0.01,0) [0|100] "PCT"  BMS
 SG_ isolationResInternal_BMS17 : 23|16@0+ (2,0) [0|130000] "kOhm"  BMS
 SG_ isolationResExternal_BMS17 : 7|16@0+ (2,0) [0|130000] "kOhm"  BMS

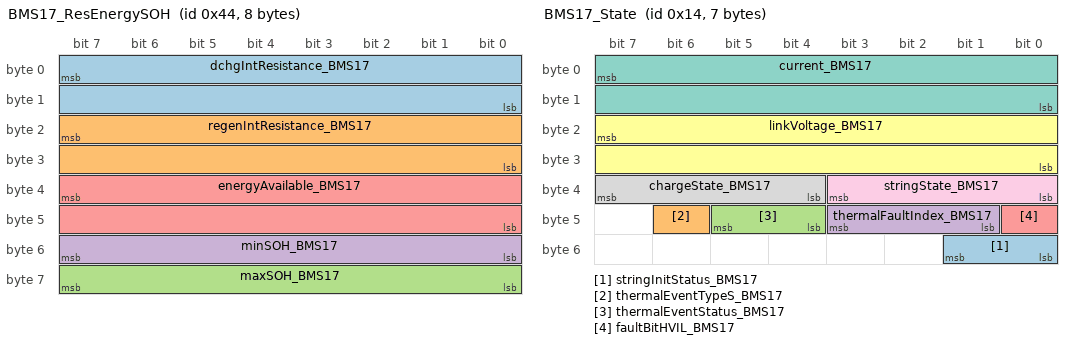
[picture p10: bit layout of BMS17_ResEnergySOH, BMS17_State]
BO_ 68 BMS17_ResEnergySOH: 8 BMS17
 SG_ dchgIntResistance_BMS17 : 7|16@0+ (0.05,0) [0|3276.75] "mOhm"  BMS
 SG_ regenIntResistance_BMS17 : 23|16@0+ (0.05,0) [0|3276.75] "mOhm"  BMS
 SG_ maxSOH_BMS17 : 63|8@0+ (0.5,0) [0|120] "PCT"  BMS
 SG_ minSOH_BMS17 : 55|8@0+ (0.5,0) [0|120] "PCT"  BMS
 SG_ energyAvailable_BMS17 : 39|16@0+ (0.01,0) [0|650] "kWh"  BMS

BO_ 116 BMS17_DriveLimits: 8 BMS17
 SG_ dchgCurrentLimit_BMS17 : 55|16@0+ (0.05,0) [0|3200] "A"  BMS
 SG_ regenCurrentLimit_BMS17 : 39|16@0+ (0.05,0) [0|3200] "A"  BMS
 SG_ minStringVLimit_BMS17 : 23|16@0+ (0.02,0) [0|1200] "V"  BMS
 SG_ maxStringVLimit_BMS17 : 7|16@0+ (0.02,0) [0|1200] "V"  BMS

BO_ 20 BMS17_State: 7 BMS17
 SG_ stringInitStatus_BMS17 : 49|2@0+ (1,0) [0|3] ""  BMS
 SG_ thermalEventTypeS_BMS17 : 46|1@0+ (1,0) [0|1] ""  BMS
 SG_ thermalEventStatus_BMS17 : 45|2@0+ (1,0) [0|2550] ""  BMS
 SG_ thermalFaultIndex_BMS17 : 43|3@0+ (1,0) [0|7] ""  BMS
 SG_ faultBitHVIL_BMS17 : 40|1@0+ (1,0) [0|1] ""  BMS
 SG_ linkVoltage_BMS17 : 23|16@0+ (0.02,0) [0|1200] "V"  BMS
 SG_ current_BMS17 : 7|16@0+ (0.1,-3200) [-3200|3353.5] "A"  BMS
 SG_ chargeState_BMS17 : 39|4@0+ (1,0) [0|15] ""  BMS
 SG_ stringState_BMS17 : 35|4@0+ (1,0) [0|0] ""  BMS

BO_ 405 BMS21_SlowDataMpex: 8 BMS21
 SG_ SW_VersionBL_BMS21 m4 : 15|32@0+ (1,0) [0|4294967295] ""  BMS
 SG_ SW_Version_BMS21 m3 : 15|32@0+ (1,0) [0|4294967295] ""  BMS
 SG_ PackSerialNumber_char20_BMS21 m2 : 55|8@0+ (1,0) [0|255] ""  BMS
 SG_ PackSerialNumber_char19_BMS21 m2 : 47|8@0+ (1,0) [0|255] ""  BMS
 SG_ PackSerialNumber_char18_BMS21 m2 : 39|8@0+ (1,0) [0|255] ""  BMS
 SG_ PackSerialNumber_char17_BMS21 m2 : 31|8@0+ (1,0) [0|255] ""  BMS
 SG_ PackSerialNumber_char16_BMS21 m2 : 23|8@0+ (1,0) [0|255] ""  BMS
 SG_ PackSerialNumber_char15_BMS21 m2 : 15|8@0+ (1,0) [0|255] ""  BMS
 SG_ PackSerialNumber_char14_BMS21 m1 : 63|8@0+ (1,0) [0|255] ""  BMS
 SG_ PackSerialNumber_char13_BMS21 m1 : 55|8@0+ (1,0) [0|255] ""  BMS
 SG_ PackSerialNumber_char12_BMS21 m1 : 47|8@0+ (1,0) [0|255] ""  BMS
 SG_ PackSerialNumber_char11_BMS21 m1 : 39|8@0+ (1,0) [0|255] ""  BMS
 SG_ PackSerialNumber_char10_BMS21 m1 : 31|8@0+ (1,0) [0|255] ""  BMS
 SG_ PackSerialNumber_char08_BMS21 m1 : 15|8@0+ (1,0) [0|255] ""  BMS
 SG_ PackSerialNumber_char09_BMS21 m1 : 23|8@0+ (1,0) [0|255] ""  BMS
 SG_ SlowDataMpx_BMS21 M : 7|8@0+ (1,0) [0|255] ""  BMS
 SG_ PackSerialNumber_char07_BMS21 m0 : 63|8@0+ (1,0) [0|255] ""  BMS
 SG_ PackSerialNumber_char06_BMS21 m0 : 55|8@0+ (1,0) [0|255] ""  BMS
 SG_ PackSerialNumber_char05_BMS21 m0 : 47|8@0+ (1,0) [0|255] ""  BMS
 SG_ PackSerialNumber_char04_BMS21 m0 : 39|8@0+ (1,0) [0|255] ""  BMS
 SG_ PackSerialNumber_char03_BMS21 m0 : 31|8@0+ (1,0) [0|255] ""  BMS
 SG_ PackSerialNumber_char02_BMS21 m0 : 23|8@0+ (1,0) [0|255] ""  BMS
 SG_ PackSerialNumber_char01_BMS21 m0 : 15|8@0+ (1,0) [0|255] ""  BMS

BO_ 533 BMS21_CoolantTemperatures: 8 BMS
 SG_ coolantOutletTemperature_BMS21 : 15|8@0+ (1,-40) [-40|215] "C"  BMS
 SG_ coolantInletTemperature_BMS21 : 7|8@0+ (1,-40) [-40|215] "C"  BMS

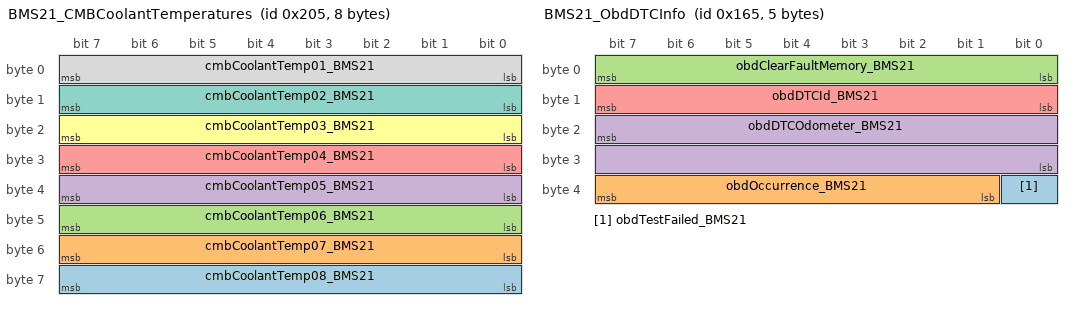
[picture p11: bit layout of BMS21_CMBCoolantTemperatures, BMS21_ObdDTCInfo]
BO_ 517 BMS21_CMBCoolantTemperatures: 8 BMS
 SG_ cmbCoolantTemp08_BMS21 : 63|8@0+ (1,-40) [-40|200] "C"  BMS
 SG_ cmbCoolantTemp07_BMS21 : 55|8@0+ (1,-40) [-40|200] "C"  BMS
 SG_ cmbCoolantTemp06_BMS21 : 47|8@0+ (1,-40) [-40|200] "C"  BMS
 SG_ cmbCoolantTemp05_BMS21 : 39|8@0+ (1,-40) [-40|200] "C"  BMS
 SG_ cmbCoolantTemp04_BMS21 : 31|8@0+ (1,-40) [-40|200] "C"  BMS
 SG_ cmbCoolantTemp03_BMS21 : 23|8@0+ (1,-40) [-40|200] "C"  BMS
 SG_ cmbCoolantTemp02_BMS21 : 15|8@0+ (1,-40) [-40|200] "C"  BMS
 SG_ cmbCoolantTemp01_BMS21 : 7|8@0+ (1,-40) [-40|200] "C"  BMS

BO_ 389 BMS21_EnergyThroughput: 5 BMS21
 SG_ maxFluidPressureInlet_BMS21 : 39|8@0+ (10,0) [0|2550] "mbar"  BMS
 SG_ energyThroughput_KWh_BMS21 : 7|32@0+ (0.01,0) [0|42949672.95] "KWh"  BMS

BO_ 357 BMS21_ObdDTCInfo: 5 BMS21
 SG_ obdTestFailed_BMS21 : 32|1@0+ (1,0) [0|1] ""  BMS
 SG_ obdOccurrence_BMS21 : 39|7@0+ (1,0) [0|126] ""  BMS
 SG_ obdClearFaultMemory_BMS21 : 7|8@0+ (1,0) [0|1] ""  BMS
 SG_ obdDTCOdometer_BMS21 : 23|16@0+ (1,0) [0|65535] "km"  BMS
 SG_ obdDTCId_BMS21 : 15|8@0+ (1,0) [0|255] ""  BMS

BO_ 341 BMS21_SOCIndeces: 4 BMS21
 SG_ maxSOCIndex_BMS21 : 23|16@0+ (1,0) [0|65535] ""  BMS
 SG_ minSOCIndex_BMS21 : 7|16@0+ (1,0) [0|65535] ""  BMS

BO_ 325 BMS21_Charge: 8 BMS21
 SG_ cusDschrgEnrgyLifeTime_BMS21 : 55|16@0+ (0.1,0) [0|1310.7] "MWh"  BMS
 SG_ cusChrgEnrgyLifeTime_BMS21 : 39|16@0+ (0.1,0) [0|1310.7] "MWh"  BMS
 SG_ chargeEnergyAvailable_BMS21 : 7|16@0+ (0.01,0) [0|0] "kWh"  BMS

BO_ 213 BMS21_StringShutdown: 3 BMS21
 SG_ stringShutdownTarget_BMS21 : 19|4@0+ (1,0) [0|0] ""  BMS
 SG_ stringShutdownTimer_BMS21 : 7|16@0+ (1,0) [0|0] ""  BMS

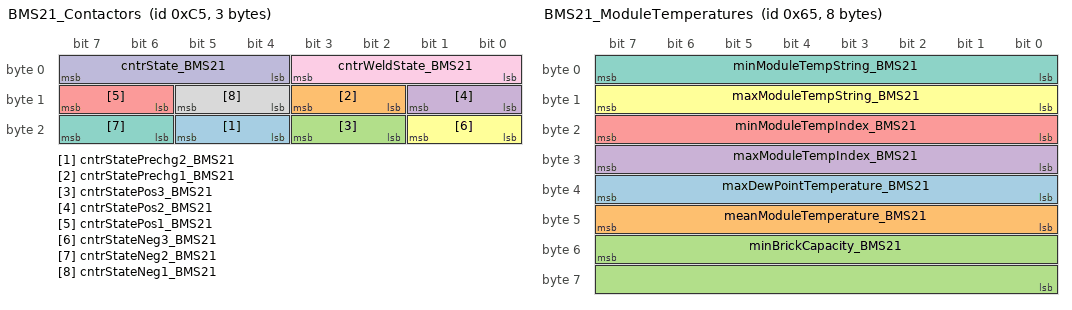
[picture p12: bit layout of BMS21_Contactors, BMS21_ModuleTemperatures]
BO_ 197 BMS21_Contactors: 3 BMS21
 SG_ cntrStatePrechg2_BMS21 : 21|2@0+ (1,0) [0|0] ""  BMS
 SG_ cntrStatePrechg1_BMS21 : 11|2@0+ (1,0) [0|0] ""  BMS
 SG_ cntrStatePos3_BMS21 : 19|2@0+ (1,0) [0|0] ""  BMS
 SG_ cntrStatePos2_BMS21 : 9|2@0+ (1,0) [0|0] ""  BMS
 SG_ cntrStatePos1_BMS21 : 15|2@0+ (1,0) [0|0] ""  BMS
 SG_ cntrStateNeg3_BMS21 : 17|2@0+ (1,0) [0|0] ""  BMS
 SG_ cntrStateNeg2_BMS21 : 23|2@0+ (1,0) [0|0] ""  BMS
 SG_ cntrStateNeg1_BMS21 : 13|2@0+ (1,0) [0|0] ""  BMS
 SG_ cntrWeldState_BMS21 : 3|4@0+ (1,0) [0|0] ""  BMS
 SG_ cntrState_BMS21 : 7|4@0+ (1,0) [0|0] ""  BMS

BO_ 165 BMS21_PowerPrediction: 8 BMS21
 SG_ regenPowerPredShrt_BMS21 : 39|16@0+ (0.01,0) [0|650] "kW"  BMS
 SG_ regenPowerPredLong_BMS21 : 55|16@0+ (0.01,0) [0|650] "kW"  BMS
 SG_ dchgPowerPredShrt_BMS21 : 7|16@0+ (0.01,0) [0|650] "kW"  BMS
 SG_ dchgPowerPredLong_BMS21 : 23|16@0+ (0.01,0) [0|650] "kW"  BMS

BO_ 181 BMS21_CellVLimits: 8 BMS21
 SG_ cusMaxCellVLimit_BMS21 : 23|16@0+ (0.0001,0) [0|6.5] "V"  BMS
 SG_ cusMinCellVLimit_BMS21 : 7|16@0+ (0.0001,0) [0|6.5] "V"  BMS

BO_ 149 BMS21_VoltagePrediction: 8 BMS21
 SG_ dchgVoltagePredShrt_BMS21 : 7|16@0+ (0.02,0) [0|1200] "V"  BMS
 SG_ dchgVoltagePredLong_BMS21 : 23|16@0+ (0.02,0) [0|1200] "V"  BMS
 SG_ regenVoltagePredShrt_BMS21 : 39|16@0+ (0.02,0) [0|1200] "V"  BMS
 SG_ regenVoltagePredLong_BMS21 : 55|16@0+ (0.02,0) [0|1200] "V"  BMS

BO_ 133 BMS21_CurrentPrediction: 8 BMS21
 SG_ regenCurrentPredShrt_BMS21 : 39|16@0+ (0.05,0) [0|3200] "A"  BMS
 SG_ regenCurrentPredLong_BMS21 : 55|16@0+ (0.05,0) [0|3200] "A"  BMS
 SG_ dchgCurrentPredShrt_BMS21 : 7|16@0+ (0.05,0) [0|3200] "A"  BMS
 SG_ dchgCurrentPredLong_BMS21 : 23|16@0+ (0.05,0) [0|3200] "A"  BMS

BO_ 101 BMS21_ModuleTemperatures: 8 BMS21
 SG_ maxDewPointTemperature_BMS21 : 39|8@0+ (0.5,-40) [-40|87.5] "C"  BMS
 SG_ meanModuleTemperature_BMS21 : 47|8@0+ (0.5,-40) [-40|87.5] "C"  BMS
 SG_ minBrickCapacity_BMS21 : 55|16@0+ (20,0) [0|1310700] "As"  BMS
 SG_ maxModuleTempIndex_BMS21 : 31|8@0+ (1,0) [0|255] ""  BMS
 SG_ minModuleTempIndex_BMS21 : 23|8@0+ (1,0) [0|255] ""  BMS
 SG_ maxModuleTempString_BMS21 : 15|8@0+ (0.5,-40) [-40|87.5] "C"  BMS
 SG_ minModuleTempString_BMS21 : 7|8@0+ (0.5,-40) [-40|87.5] "C"  BMS

BO_ 37 BMS21_StringVoltageCharge: 8 BMS21
 SG_ brickOpenCircuitV_BMS21 : 55|16@0+ (0.0001,0) [0|6.5] "V"  BMS
 SG_ meanSOC_BMS21 : 39|16@0+ (0.01,0) [0|100] "PCT"  BMS
 SG_ stringVoltage_BMS21 : 7|16@0+ (0.02,0) [0|1200] "V"  BMS
 SG_ chargerCurrentLimit_BMS21 : 23|16@0+ (0.05,0) [0|3200] "A"  BMS

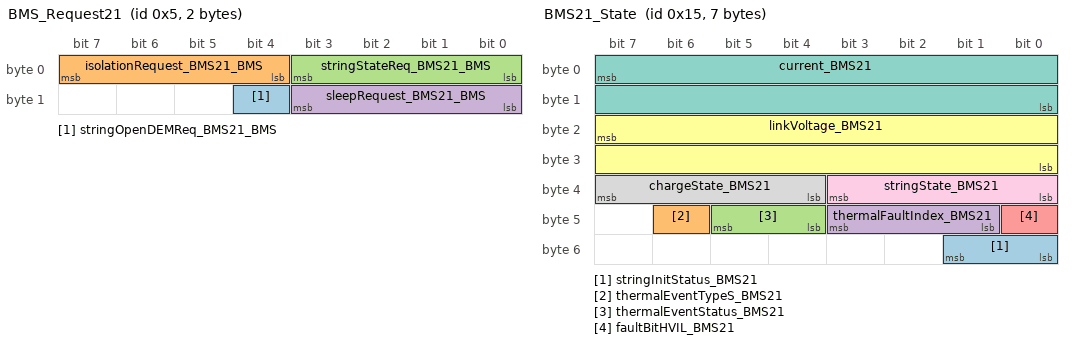
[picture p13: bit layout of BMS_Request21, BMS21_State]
BO_ 5 BMS_Request21: 2 BMS
 SG_ stringOpenDEMReq_BMS21_BMS : 12|1@0+ (1,0) [0|0] ""  BMS
 SG_ isolationRequest_BMS21_BMS : 7|4@0+ (1,0) [0|0] ""  BMS
 SG_ stringStateReq_BMS21_BMS : 3|4@0+ (1,0) [0|0] ""  BMS
 SG_ sleepRequest_BMS21_BMS : 11|4@0+ (1,0) [0|0] ""  BMS

BO_ 85 BMS21_BrickVoltages: 8 BMS21
 SG_ maxBrickVoltageIndex_BMS21 : 55|16@0+ (1,0) [0|65535] ""  BMS
 SG_ minBrickVoltageIndex_BMS21 : 39|16@0+ (1,0) [0|65535] ""  BMS
 SG_ minBrickVoltage_BMS21 : 7|16@0+ (0.0001,0) [0|6.5] "V"  BMS
 SG_ maxBrickVoltage_BMS21 : 23|16@0+ (0.0001,0) [0|6.5] "V"  BMS

BO_ 53 BMS21_IsolationSOC: 8 BMS21
 SG_ maxSOC_BMS21 : 55|16@0+ (0.01,0) [0|100] "PCT"  BMS
 SG_ minSOC_BMS21 : 39|16@0+ (0.01,0) [0|100] "PCT"  BMS
 SG_ isolationResInternal_BMS21 : 23|16@0+ (2,0) [0|130000] "kOhm"  BMS
 SG_ isolationResExternal_BMS21 : 7|16@0+ (2,0) [0|130000] "kOhm"  BMS

BO_ 69 BMS21_ResEnergySOH: 8 BMS21
 SG_ dchgIntResistance_BMS21 : 7|16@0+ (0.05,0) [0|3276.75] "mOhm"  BMS
 SG_ regenIntResistance_BMS21 : 23|16@0+ (0.05,0) [0|3276.75] "mOhm"  BMS
 SG_ maxSOH_BMS21 : 63|8@0+ (0.5,0) [0|120] "PCT"  BMS
 SG_ minSOH_BMS21 : 55|8@0+ (0.5,0) [0|120] "PCT"  BMS
 SG_ energyAvailable_BMS21 : 39|16@0+ (0.01,0) [0|650] "kWh"  BMS

BO_ 117 BMS21_DriveLimits: 8 BMS21
 SG_ dchgCurrentLimit_BMS21 : 55|16@0+ (0.05,0) [0|3200] "A"  BMS
 SG_ regenCurrentLimit_BMS21 : 39|16@0+ (0.05,0) [0|3200] "A"  BMS
 SG_ minStringVLimit_BMS21 : 23|16@0+ (0.02,0) [0|1200] "V"  BMS
 SG_ maxStringVLimit_BMS21 : 7|16@0+ (0.02,0) [0|1200] "V"  BMS

BO_ 21 BMS21_State: 7 BMS21
 SG_ stringInitStatus_BMS21 : 49|2@0+ (1,0) [0|3] ""  BMS
 SG_ thermalEventTypeS_BMS21 : 46|1@0+ (1,0) [0|1] ""  BMS
 SG_ thermalEventStatus_BMS21 : 45|2@0+ (1,0) [0|2550] ""  BMS
 SG_ thermalFaultIndex_BMS21 : 43|3@0+ (1,0) [0|7] ""  BMS
 SG_ faultBitHVIL_BMS21 : 40|1@0+ (1,0) [0|1] ""  BMS
 SG_ linkVoltage_BMS21 : 23|16@0+ (0.02,0) [0|1200] "V"  BMS
 SG_ current_BMS21 : 7|16@0+ (0.1,-3200) [-3200|3353.5] "A"  BMS
 SG_ chargeState_BMS21 : 39|4@0+ (1,0) [0|15] ""  BMS
 SG_ stringState_BMS21 : 35|4@0+ (1,0) [0|0] ""  BMS

BO_ 406 BMS25_SlowDataMpex: 8 BMS25
 SG_ SW_VersionBL_BMS25 m4 : 15|32@0+ (1,0) [0|4294967295] ""  BMS
 SG_ SW_Version_BMS25 m3 : 15|32@0+ (1,0) [0|4294967295] ""  BMS
 SG_ PackSerialNumber_char20_BMS25 m2 : 55|8@0+ (1,0) [0|255] ""  BMS
 SG_ PackSerialNumber_char19_BMS25 m2 : 47|8@0+ (1,0) [0|255] ""  BMS
 SG_ PackSerialNumber_char18_BMS25 m2 : 39|8@0+ (1,0) [0|255] ""  BMS
 SG_ PackSerialNumber_char17_BMS25 m2 : 31|8@0+ (1,0) [0|255] ""  BMS
 SG_ PackSerialNumber_char16_BMS25 m2 : 23|8@0+ (1,0) [0|255] ""  BMS
 SG_ PackSerialNumber_char15_BMS25 m2 : 15|8@0+ (1,0) [0|255] ""  BMS
 SG_ PackSerialNumber_char14_BMS25 m1 : 63|8@0+ (1,0) [0|255] ""  BMS
 SG_ PackSerialNumber_char13_BMS25 m1 : 55|8@0+ (1,0) [0|255] ""  BMS
 SG_ PackSerialNumber_char12_BMS25 m1 : 47|8@0+ (1,0) [0|255] ""  BMS
 SG_ PackSerialNumber_char11_BMS25 m1 : 39|8@0+ (1,0) [0|255] ""  BMS
 SG_ PackSerialNumber_char10_BMS25 m1 : 31|8@0+ (1,0) [0|255] ""  BMS
 SG_ PackSerialNumber_char08_BMS25 m1 : 15|8@0+ (1,0) [0|255] ""  BMS
 SG_ PackSerialNumber_char09_BMS25 m1 : 23|8@0+ (1,0) [0|255] ""  BMS
 SG_ SlowDataMpx_BMS25 M : 7|8@0+ (1,0) [0|255] ""  BMS
 SG_ PackSerialNumber_char07_BMS25 m0 : 63|8@0+ (1,0) [0|255] ""  BMS
 SG_ PackSerialNumber_char06_BMS25 m0 : 55|8@0+ (1,0) [0|255] ""  BMS
 SG_ PackSerialNumber_char05_BMS25 m0 : 47|8@0+ (1,0) [0|255] ""  BMS
 SG_ PackSerialNumber_char04_BMS25 m0 : 39|8@0+ (1,0) [0|255] ""  BMS
 SG_ PackSerialNumber_char03_BMS25 m0 : 31|8@0+ (1,0) [0|255] ""  BMS
 SG_ PackSerialNumber_char02_BMS25 m0 : 23|8@0+ (1,0) [0|255] ""  BMS
 SG_ PackSerialNumber_char01_BMS25 m0 : 15|8@0+ (1,0) [0|255] ""  BMS

BO_ 534 BMS25_CoolantTemperatures: 8 BMS
 SG_ coolantOutletTemperature_BMS25 : 15|8@0+ (1,-40) [-40|215] "C"  BMS
 SG_ coolantInletTemperature_BMS25 : 7|8@0+ (1,-40) [-40|215] "C"  BMS

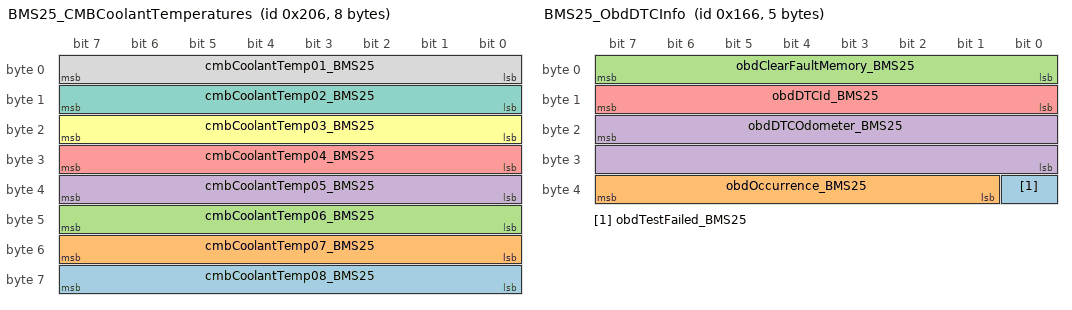
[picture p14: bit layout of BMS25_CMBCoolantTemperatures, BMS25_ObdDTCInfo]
BO_ 518 BMS25_CMBCoolantTemperatures: 8 BMS
 SG_ cmbCoolantTemp08_BMS25 : 63|8@0+ (1,-40) [-40|200] "C"  BMS
 SG_ cmbCoolantTemp07_BMS25 : 55|8@0+ (1,-40) [-40|200] "C"  BMS
 SG_ cmbCoolantTemp06_BMS25 : 47|8@0+ (1,-40) [-40|200] "C"  BMS
 SG_ cmbCoolantTemp05_BMS25 : 39|8@0+ (1,-40) [-40|200] "C"  BMS
 SG_ cmbCoolantTemp04_BMS25 : 31|8@0+ (1,-40) [-40|200] "C"  BMS
 SG_ cmbCoolantTemp03_BMS25 : 23|8@0+ (1,-40) [-40|200] "C"  BMS
 SG_ cmbCoolantTemp02_BMS25 : 15|8@0+ (1,-40) [-40|200] "C"  BMS
 SG_ cmbCoolantTemp01_BMS25 : 7|8@0+ (1,-40) [-40|200] "C"  BMS

BO_ 390 BMS25_EnergyThroughput: 5 BMS25
 SG_ maxFluidPressureInlet_BMS25 : 39|8@0+ (10,0) [0|2550] "mbar"  BMS
 SG_ energyThroughput_KWh_BMS25 : 7|32@0+ (0.01,0) [0|42949672.95] "KWh"  BMS

BO_ 358 BMS25_ObdDTCInfo: 5 BMS25
 SG_ obdTestFailed_BMS25 : 32|1@0+ (1,0) [0|1] ""  BMS
 SG_ obdOccurrence_BMS25 : 39|7@0+ (1,0) [0|126] ""  BMS
 SG_ obdClearFaultMemory_BMS25 : 7|8@0+ (1,0) [0|1] ""  BMS
 SG_ obdDTCOdometer_BMS25 : 23|16@0+ (1,0) [0|65535] "km"  BMS
 SG_ obdDTCId_BMS25 : 15|8@0+ (1,0) [0|255] ""  BMS

BO_ 342 BMS25_SOCIndeces: 4 BMS25
 SG_ maxSOCIndex_BMS25 : 23|16@0+ (1,0) [0|65535] ""  BMS
 SG_ minSOCIndex_BMS25 : 7|16@0+ (1,0) [0|65535] ""  BMS

BO_ 326 BMS25_Charge: 8 BMS25
 SG_ cusDschrgEnrgyLifeTime_BMS25 : 55|16@0+ (0.1,0) [0|1310.7] "MWh"  BMS
 SG_ cusChrgEnrgyLifeTime_BMS25 : 39|16@0+ (0.1,0) [0|1310.7] "MWh"  BMS
 SG_ chargeEnergyAvailable_BMS25 : 7|16@0+ (0.01,0) [0|0] "kWh"  BMS

BO_ 214 BMS25_StringShutdown: 3 BMS25
 SG_ stringShutdownTarget_BMS25 : 19|4@0+ (1,0) [0|0] ""  BMS
 SG_ stringShutdownTimer_BMS25 : 7|16@0+ (1,0) [0|0] ""  BMS

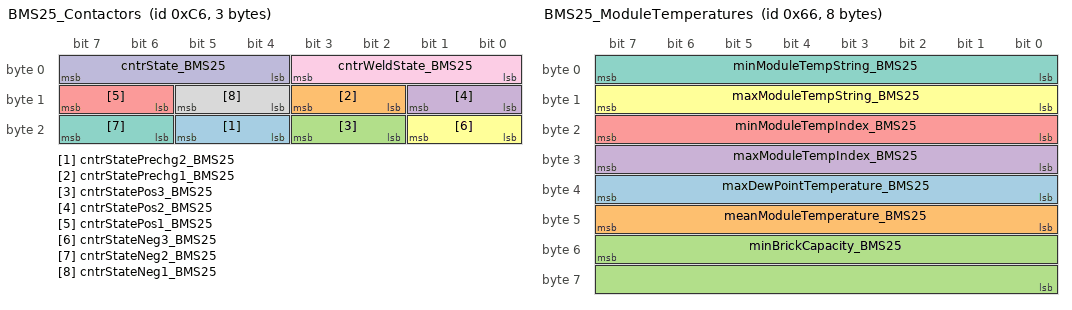
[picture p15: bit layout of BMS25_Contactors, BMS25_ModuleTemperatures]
BO_ 198 BMS25_Contactors: 3 BMS25
 SG_ cntrStatePrechg2_BMS25 : 21|2@0+ (1,0) [0|0] ""  BMS
 SG_ cntrStatePrechg1_BMS25 : 11|2@0+ (1,0) [0|0] ""  BMS
 SG_ cntrStatePos3_BMS25 : 19|2@0+ (1,0) [0|0] ""  BMS
 SG_ cntrStatePos2_BMS25 : 9|2@0+ (1,0) [0|0] ""  BMS
 SG_ cntrStatePos1_BMS25 : 15|2@0+ (1,0) [0|0] ""  BMS
 SG_ cntrStateNeg3_BMS25 : 17|2@0+ (1,0) [0|0] ""  BMS
 SG_ cntrStateNeg2_BMS25 : 23|2@0+ (1,0) [0|0] ""  BMS
 SG_ cntrStateNeg1_BMS25 : 13|2@0+ (1,0) [0|0] ""  BMS
 SG_ cntrWeldState_BMS25 : 3|4@0+ (1,0) [0|0] ""  BMS
 SG_ cntrState_BMS25 : 7|4@0+ (1,0) [0|0] ""  BMS

BO_ 166 BMS25_PowerPrediction: 8 BMS25
 SG_ regenPowerPredShrt_BMS25 : 39|16@0+ (0.01,0) [0|650] "kW"  BMS
 SG_ regenPowerPredLong_BMS25 : 55|16@0+ (0.01,0) [0|650] "kW"  BMS
 SG_ dchgPowerPredShrt_BMS25 : 7|16@0+ (0.01,0) [0|650] "kW"  BMS
 SG_ dchgPowerPredLong_BMS25 : 23|16@0+ (0.01,0) [0|650] "kW"  BMS

BO_ 182 BMS25_CellVLimits: 8 BMS25
 SG_ cusMaxCellVLimit_BMS25 : 23|16@0+ (0.0001,0) [0|6.5] "V"  BMS
 SG_ cusMinCellVLimit_BMS25 : 7|16@0+ (0.0001,0) [0|6.5] "V"  BMS

BO_ 150 BMS25_VoltagePrediction: 8 BMS25
 SG_ dchgVoltagePredShrt_BMS25 : 7|16@0+ (0.02,0) [0|1200] "V"  BMS
 SG_ dchgVoltagePredLong_BMS25 : 23|16@0+ (0.02,0) [0|1200] "V"  BMS
 SG_ regenVoltagePredShrt_BMS25 : 39|16@0+ (0.02,0) [0|1200] "V"  BMS
 SG_ regenVoltagePredLong_BMS25 : 55|16@0+ (0.02,0) [0|1200] "V"  BMS

BO_ 134 BMS25_CurrentPrediction: 8 BMS25
 SG_ regenCurrentPredShrt_BMS25 : 39|16@0+ (0.05,0) [0|3200] "A"  BMS
 SG_ regenCurrentPredLong_BMS25 : 55|16@0+ (0.05,0) [0|3200] "A"  BMS
 SG_ dchgCurrentPredShrt_BMS25 : 7|16@0+ (0.05,0) [0|3200] "A"  BMS
 SG_ dchgCurrentPredLong_BMS25 : 23|16@0+ (0.05,0) [0|3200] "A"  BMS

BO_ 102 BMS25_ModuleTemperatures: 8 BMS25
 SG_ maxDewPointTemperature_BMS25 : 39|8@0+ (0.5,-40) [-40|87.5] "C"  BMS
 SG_ meanModuleTemperature_BMS25 : 47|8@0+ (0.5,-40) [-40|87.5] "C"  BMS
 SG_ minBrickCapacity_BMS25 : 55|16@0+ (20,0) [0|1310700] "As"  BMS
 SG_ maxModuleTempIndex_BMS25 : 31|8@0+ (1,0) [0|255] ""  BMS
 SG_ minModuleTempIndex_BMS25 : 23|8@0+ (1,0) [0|255] ""  BMS
 SG_ maxModuleTempString_BMS25 : 15|8@0+ (0.5,-40) [-40|87.5] "C"  BMS
 SG_ minModuleTempString_BMS25 : 7|8@0+ (0.5,-40) [-40|87.5] "C"  BMS

BO_ 38 BMS25_StringVoltageCharge: 8 BMS25
 SG_ brickOpenCircuitV_BMS25 : 55|16@0+ (0.0001,0) [0|6.5] "V"  BMS
 SG_ meanSOC_BMS25 : 39|16@0+ (0.01,0) [0|100] "PCT"  BMS
 SG_ stringVoltage_BMS25 : 7|16@0+ (0.02,0) [0|1200] "V"  BMS
 SG_ chargerCurrentLimit_BMS25 : 23|16@0+ (0.05,0) [0|3200] "A"  BMS

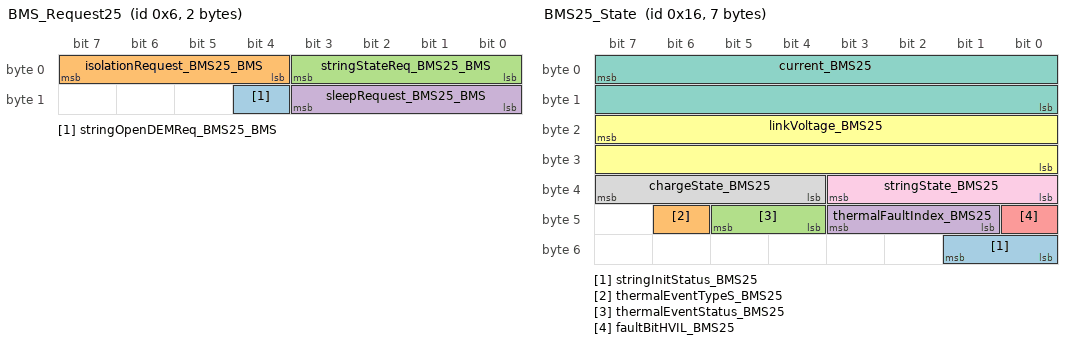
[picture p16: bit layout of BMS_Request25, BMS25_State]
BO_ 6 BMS_Request25: 2 BMS
 SG_ stringOpenDEMReq_BMS25_BMS : 12|1@0+ (1,0) [0|0] ""  BMS
 SG_ isolationRequest_BMS25_BMS : 7|4@0+ (1,0) [0|0] ""  BMS
 SG_ stringStateReq_BMS25_BMS : 3|4@0+ (1,0) [0|0] ""  BMS
 SG_ sleepRequest_BMS25_BMS : 11|4@0+ (1,0) [0|0] ""  BMS

BO_ 86 BMS25_BrickVoltages: 8 BMS25
 SG_ maxBrickVoltageIndex_BMS25 : 55|16@0+ (1,0) [0|65535] ""  BMS
 SG_ minBrickVoltageIndex_BMS25 : 39|16@0+ (1,0) [0|65535] ""  BMS
 SG_ minBrickVoltage_BMS25 : 7|16@0+ (0.0001,0) [0|6.5] "V"  BMS
 SG_ maxBrickVoltage_BMS25 : 23|16@0+ (0.0001,0) [0|6.5] "V"  BMS

BO_ 54 BMS25_IsolationSOC: 8 BMS25
 SG_ maxSOC_BMS25 : 55|16@0+ (0.01,0) [0|100] "PCT"  BMS
 SG_ minSOC_BMS25 : 39|16@0+ (0.01,0) [0|100] "PCT"  BMS
 SG_ isolationResInternal_BMS25 : 23|16@0+ (2,0) [0|130000] "kOhm"  BMS
 SG_ isolationResExternal_BMS25 : 7|16@0+ (2,0) [0|130000] "kOhm"  BMS

BO_ 70 BMS25_ResEnergySOH: 8 BMS25
 SG_ dchgIntResistance_BMS25 : 7|16@0+ (0.05,0) [0|3276.75] "mOhm"  BMS
 SG_ regenIntResistance_BMS25 : 23|16@0+ (0.05,0) [0|3276.75] "mOhm"  BMS
 SG_ maxSOH_BMS25 : 63|8@0+ (0.5,0) [0|120] "PCT"  BMS
 SG_ minSOH_BMS25 : 55|8@0+ (0.5,0) [0|120] "PCT"  BMS
 SG_ energyAvailable_BMS25 : 39|16@0+ (0.01,0) [0|650] "kWh"  BMS

BO_ 118 BMS25_DriveLimits: 8 BMS25
 SG_ dchgCurrentLimit_BMS25 : 55|16@0+ (0.05,0) [0|3200] "A"  BMS
 SG_ regenCurrentLimit_BMS25 : 39|16@0+ (0.05,0) [0|3200] "A"  BMS
 SG_ minStringVLimit_BMS25 : 23|16@0+ (0.02,0) [0|1200] "V"  BMS
 SG_ maxStringVLimit_BMS25 : 7|16@0+ (0.02,0) [0|1200] "V"  BMS

BO_ 22 BMS25_State: 7 BMS25
 SG_ stringInitStatus_BMS25 : 49|2@0+ (1,0) [0|3] ""  BMS
 SG_ thermalEventTypeS_BMS25 : 46|1@0+ (1,0) [0|1] ""  BMS
 SG_ thermalEventStatus_BMS25 : 45|2@0+ (1,0) [0|2550] ""  BMS
 SG_ thermalFaultIndex_BMS25 : 43|3@0+ (1,0) [0|7] ""  BMS
 SG_ faultBitHVIL_BMS25 : 40|1@0+ (1,0) [0|1] ""  BMS
 SG_ linkVoltage_BMS25 : 23|16@0+ (0.02,0) [0|1200] "V"  BMS
 SG_ current_BMS25 : 7|16@0+ (0.1,-3200) [-3200|3353.5] "A"  BMS
 SG_ chargeState_BMS25 : 39|4@0+ (1,0) [0|15] ""  BMS
 SG_ stringState_BMS25 : 35|4@0+ (1,0) [0|0] ""  BMS

BO_ 407 BMS29_SlowDataMpex: 8 BMS29
 SG_ SW_VersionBL_BMS29 m4 : 15|32@0+ (1,0) [0|4294967295] ""  BMS
 SG_ SW_Version_BMS29 m3 : 15|32@0+ (1,0) [0|4294967295] ""  BMS
 SG_ PackSerialNumber_char20_BMS29 m2 : 55|8@0+ (1,0) [0|255] ""  BMS
 SG_ PackSerialNumber_char19_BMS29 m2 : 47|8@0+ (1,0) [0|255] ""  BMS
 SG_ PackSerialNumber_char18_BMS29 m2 : 39|8@0+ (1,0) [0|255] ""  BMS
 SG_ PackSerialNumber_char17_BMS29 m2 : 31|8@0+ (1,0) [0|255] ""  BMS
 SG_ PackSerialNumber_char16_BMS29 m2 : 23|8@0+ (1,0) [0|255] ""  BMS
 SG_ PackSerialNumber_char15_BMS29 m2 : 15|8@0+ (1,0) [0|255] ""  BMS
 SG_ PackSerialNumber_char14_BMS29 m1 : 63|8@0+ (1,0) [0|255] ""  BMS
 SG_ PackSerialNumber_char13_BMS29 m1 : 55|8@0+ (1,0) [0|255] ""  BMS
 SG_ PackSerialNumber_char12_BMS29 m1 : 47|8@0+ (1,0) [0|255] ""  BMS
 SG_ PackSerialNumber_char11_BMS29 m1 : 39|8@0+ (1,0) [0|255] ""  BMS
 SG_ PackSerialNumber_char10_BMS29 m1 : 31|8@0+ (1,0) [0|255] ""  BMS
 SG_ PackSerialNumber_char08_BMS29 m1 : 15|8@0+ (1,0) [0|255] ""  BMS
 SG_ PackSerialNumber_char09_BMS29 m1 : 23|8@0+ (1,0) [0|255] ""  BMS
 SG_ SlowDataMpx_BMS29 M : 7|8@0+ (1,0) [0|255] ""  BMS
 SG_ PackSerialNumber_char07_BMS29 m0 : 63|8@0+ (1,0) [0|255] ""  BMS
 SG_ PackSerialNumber_char06_BMS29 m0 : 55|8@0+ (1,0) [0|255] ""  BMS
 SG_ PackSerialNumber_char05_BMS29 m0 : 47|8@0+ (1,0) [0|255] ""  BMS
 SG_ PackSerialNumber_char04_BMS29 m0 : 39|8@0+ (1,0) [0|255] ""  BMS
 SG_ PackSerialNumber_char03_BMS29 m0 : 31|8@0+ (1,0) [0|255] ""  BMS
 SG_ PackSerialNumber_char02_BMS29 m0 : 23|8@0+ (1,0) [0|255] ""  BMS
 SG_ PackSerialNumber_char01_BMS29 m0 : 15|8@0+ (1,0) [0|255] ""  BMS

BO_ 535 BMS29_CoolantTemperatures: 8 BMS
 SG_ coolantOutletTemperature_BMS29 : 15|8@0+ (1,-40) [-40|215] "C"  BMS
 SG_ coolantInletTemperature_BMS29 : 7|8@0+ (1,-40) [-40|215] "C"  BMS

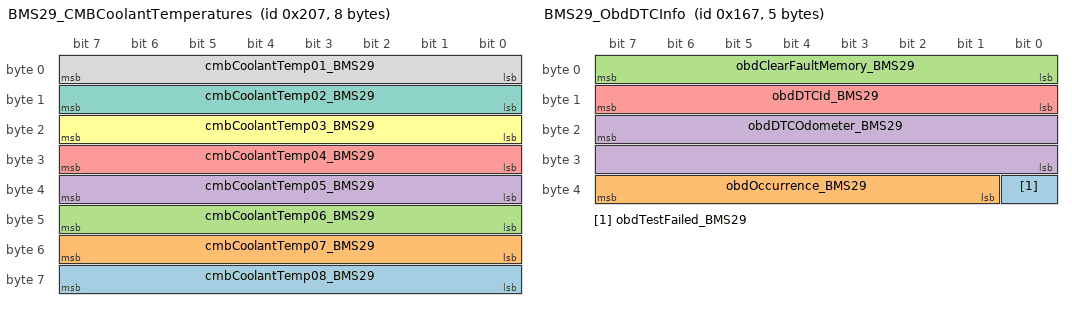
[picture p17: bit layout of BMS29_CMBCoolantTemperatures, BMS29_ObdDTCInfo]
BO_ 519 BMS29_CMBCoolantTemperatures: 8 BMS
 SG_ cmbCoolantTemp08_BMS29 : 63|8@0+ (1,-40) [-40|200] "C"  BMS
 SG_ cmbCoolantTemp07_BMS29 : 55|8@0+ (1,-40) [-40|200] "C"  BMS
 SG_ cmbCoolantTemp06_BMS29 : 47|8@0+ (1,-40) [-40|200] "C"  BMS
 SG_ cmbCoolantTemp05_BMS29 : 39|8@0+ (1,-40) [-40|200] "C"  BMS
 SG_ cmbCoolantTemp04_BMS29 : 31|8@0+ (1,-40) [-40|200] "C"  BMS
 SG_ cmbCoolantTemp03_BMS29 : 23|8@0+ (1,-40) [-40|200] "C"  BMS
 SG_ cmbCoolantTemp02_BMS29 : 15|8@0+ (1,-40) [-40|200] "C"  BMS
 SG_ cmbCoolantTemp01_BMS29 : 7|8@0+ (1,-40) [-40|200] "C"  BMS

BO_ 391 BMS29_EnergyThroughput: 5 BMS29
 SG_ maxFluidPressureInlet_BMS29 : 39|8@0+ (10,0) [0|2550] "mbar"  BMS
 SG_ energyThroughput_KWh_BMS29 : 7|32@0+ (0.01,0) [0|42949672.95] "KWh"  BMS

BO_ 359 BMS29_ObdDTCInfo: 5 BMS29
 SG_ obdTestFailed_BMS29 : 32|1@0+ (1,0) [0|1] ""  BMS
 SG_ obdOccurrence_BMS29 : 39|7@0+ (1,0) [0|126] ""  BMS
 SG_ obdClearFaultMemory_BMS29 : 7|8@0+ (1,0) [0|1] ""  BMS
 SG_ obdDTCOdometer_BMS29 : 23|16@0+ (1,0) [0|65535] "km"  BMS
 SG_ obdDTCId_BMS29 : 15|8@0+ (1,0) [0|255] ""  BMS

BO_ 343 BMS29_SOCIndeces: 4 BMS29
 SG_ maxSOCIndex_BMS29 : 23|16@0+ (1,0) [0|65535] ""  BMS
 SG_ minSOCIndex_BMS29 : 7|16@0+ (1,0) [0|65535] ""  BMS

BO_ 327 BMS29_Charge: 8 BMS29
 SG_ cusDschrgEnrgyLifeTime_BMS29 : 55|16@0+ (0.1,0) [0|1310.7] "MWh"  BMS
 SG_ cusChrgEnrgyLifeTime_BMS29 : 39|16@0+ (0.1,0) [0|1310.7] "MWh"  BMS
 SG_ chargeEnergyAvailable_BMS29 : 7|16@0+ (0.01,0) [0|0] "kWh"  BMS

BO_ 215 BMS29_StringShutdown: 3 BMS29
 SG_ stringShutdownTarget_BMS29 : 19|4@0+ (1,0) [0|0] ""  BMS
 SG_ stringShutdownTimer_BMS29 : 7|16@0+ (1,0) [0|0] ""  BMS

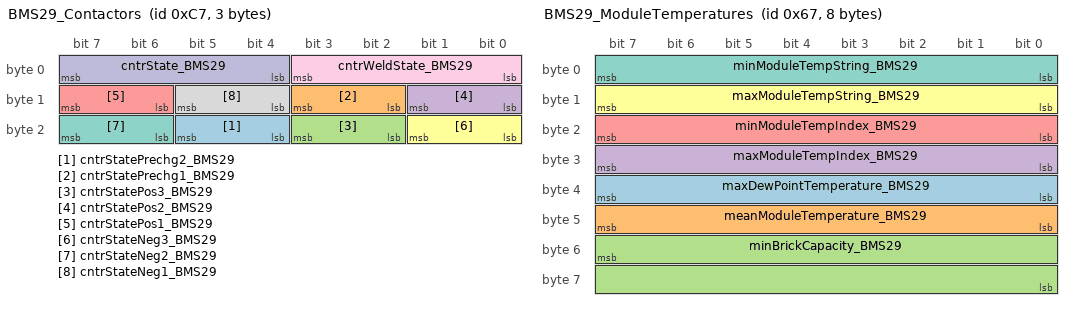
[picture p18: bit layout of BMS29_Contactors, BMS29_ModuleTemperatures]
BO_ 199 BMS29_Contactors: 3 BMS29
 SG_ cntrStatePrechg2_BMS29 : 21|2@0+ (1,0) [0|0] ""  BMS
 SG_ cntrStatePrechg1_BMS29 : 11|2@0+ (1,0) [0|0] ""  BMS
 SG_ cntrStatePos3_BMS29 : 19|2@0+ (1,0) [0|0] ""  BMS
 SG_ cntrStatePos2_BMS29 : 9|2@0+ (1,0) [0|0] ""  BMS
 SG_ cntrStatePos1_BMS29 : 15|2@0+ (1,0) [0|0] ""  BMS
 SG_ cntrStateNeg3_BMS29 : 17|2@0+ (1,0) [0|0] ""  BMS
 SG_ cntrStateNeg2_BMS29 : 23|2@0+ (1,0) [0|0] ""  BMS
 SG_ cntrStateNeg1_BMS29 : 13|2@0+ (1,0) [0|0] ""  BMS
 SG_ cntrWeldState_BMS29 : 3|4@0+ (1,0) [0|0] ""  BMS
 SG_ cntrState_BMS29 : 7|4@0+ (1,0) [0|0] ""  BMS

BO_ 167 BMS29_PowerPrediction: 8 BMS29
 SG_ regenPowerPredShrt_BMS29 : 39|16@0+ (0.01,0) [0|650] "kW"  BMS
 SG_ regenPowerPredLong_BMS29 : 55|16@0+ (0.01,0) [0|650] "kW"  BMS
 SG_ dchgPowerPredShrt_BMS29 : 7|16@0+ (0.01,0) [0|650] "kW"  BMS
 SG_ dchgPowerPredLong_BMS29 : 23|16@0+ (0.01,0) [0|650] "kW"  BMS

BO_ 183 BMS29_CellVLimits: 8 BMS29
 SG_ cusMaxCellVLimit_BMS29 : 23|16@0+ (0.0001,0) [0|6.5] "V"  BMS
 SG_ cusMinCellVLimit_BMS29 : 7|16@0+ (0.0001,0) [0|6.5] "V"  BMS

BO_ 151 BMS29_VoltagePrediction: 8 BMS29
 SG_ dchgVoltagePredShrt_BMS29 : 7|16@0+ (0.02,0) [0|1200] "V"  BMS
 SG_ dchgVoltagePredLong_BMS29 : 23|16@0+ (0.02,0) [0|1200] "V"  BMS
 SG_ regenVoltagePredShrt_BMS29 : 39|16@0+ (0.02,0) [0|1200] "V"  BMS
 SG_ regenVoltagePredLong_BMS29 : 55|16@0+ (0.02,0) [0|1200] "V"  BMS

BO_ 135 BMS29_CurrentPrediction: 8 BMS29
 SG_ regenCurrentPredShrt_BMS29 : 39|16@0+ (0.05,0) [0|3200] "A"  BMS
 SG_ regenCurrentPredLong_BMS29 : 55|16@0+ (0.05,0) [0|3200] "A"  BMS
 SG_ dchgCurrentPredShrt_BMS29 : 7|16@0+ (0.05,0) [0|3200] "A"  BMS
 SG_ dchgCurrentPredLong_BMS29 : 23|16@0+ (0.05,0) [0|3200] "A"  BMS

BO_ 103 BMS29_ModuleTemperatures: 8 BMS29
 SG_ maxDewPointTemperature_BMS29 : 39|8@0+ (0.5,-40) [-40|87.5] "C"  BMS
 SG_ meanModuleTemperature_BMS29 : 47|8@0+ (0.5,-40) [-40|87.5] "C"  BMS
 SG_ minBrickCapacity_BMS29 : 55|16@0+ (20,0) [0|1310700] "As"  BMS
 SG_ maxModuleTempIndex_BMS29 : 31|8@0+ (1,0) [0|255] ""  BMS
 SG_ minModuleTempIndex_BMS29 : 23|8@0+ (1,0) [0|255] ""  BMS
 SG_ maxModuleTempString_BMS29 : 15|8@0+ (0.5,-40) [-40|87.5] "C"  BMS
 SG_ minModuleTempString_BMS29 : 7|8@0+ (0.5,-40) [-40|87.5] "C"  BMS

BO_ 39 BMS29_StringVoltageCharge: 8 BMS29
 SG_ brickOpenCircuitV_BMS29 : 55|16@0+ (0.0001,0) [0|6.5] "V"  BMS
 SG_ meanSOC_BMS29 : 39|16@0+ (0.01,0) [0|100] "PCT"  BMS
 SG_ stringVoltage_BMS29 : 7|16@0+ (0.02,0) [0|1200] "V"  BMS
 SG_ chargerCurrentLimit_BMS29 : 23|16@0+ (0.05,0) [0|3200] "A"  BMS

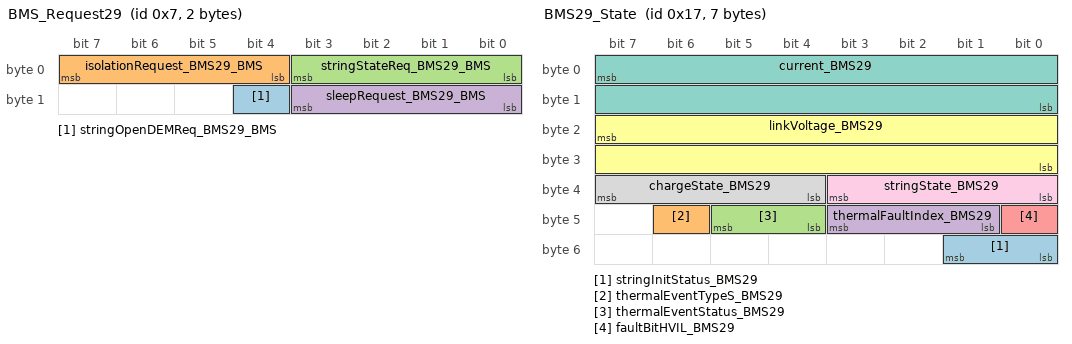
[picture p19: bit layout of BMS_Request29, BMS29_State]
BO_ 7 BMS_Request29: 2 BMS
 SG_ stringOpenDEMReq_BMS29_BMS : 12|1@0+ (1,0) [0|0] ""  BMS
 SG_ isolationRequest_BMS29_BMS : 7|4@0+ (1,0) [0|0] ""  BMS
 SG_ stringStateReq_BMS29_BMS : 3|4@0+ (1,0) [0|0] ""  BMS
 SG_ sleepRequest_BMS29_BMS : 11|4@0+ (1,0) [0|0] ""  BMS

BO_ 87 BMS29_BrickVoltages: 8 BMS29
 SG_ maxBrickVoltageIndex_BMS29 : 55|16@0+ (1,0) [0|65535] ""  BMS
 SG_ minBrickVoltageIndex_BMS29 : 39|16@0+ (1,0) [0|65535] ""  BMS
 SG_ minBrickVoltage_BMS29 : 7|16@0+ (0.0001,0) [0|6.5] "V"  BMS
 SG_ maxBrickVoltage_BMS29 : 23|16@0+ (0.0001,0) [0|6.5] "V"  BMS

BO_ 55 BMS29_IsolationSOC: 8 BMS29
 SG_ maxSOC_BMS29 : 55|16@0+ (0.01,0) [0|100] "PCT"  BMS
 SG_ minSOC_BMS29 : 39|16@0+ (0.01,0) [0|100] "PCT"  BMS
 SG_ isolationResInternal_BMS29 : 23|16@0+ (2,0) [0|130000] "kOhm"  BMS
 SG_ isolationResExternal_BMS29 : 7|16@0+ (2,0) [0|130000] "kOhm"  BMS

BO_ 71 BMS29_ResEnergySOH: 8 BMS29
 SG_ dchgIntResistance_BMS29 : 7|16@0+ (0.05,0) [0|3276.75] "mOhm"  BMS
 SG_ regenIntResistance_BMS29 : 23|16@0+ (0.05,0) [0|3276.75] "mOhm"  BMS
 SG_ maxSOH_BMS29 : 63|8@0+ (0.5,0) [0|120] "PCT"  BMS
 SG_ minSOH_BMS29 : 55|8@0+ (0.5,0) [0|120] "PCT"  BMS
 SG_ energyAvailable_BMS29 : 39|16@0+ (0.01,0) [0|650] "kWh"  BMS

BO_ 119 BMS29_DriveLimits: 8 BMS29
 SG_ dchgCurrentLimit_BMS29 : 55|16@0+ (0.05,0) [0|3200] "A"  BMS
 SG_ regenCurrentLimit_BMS29 : 39|16@0+ (0.05,0) [0|3200] "A"  BMS
 SG_ minStringVLimit_BMS29 : 23|16@0+ (0.02,0) [0|1200] "V"  BMS
 SG_ maxStringVLimit_BMS29 : 7|16@0+ (0.02,0) [0|1200] "V"  BMS

BO_ 23 BMS29_State: 7 BMS29
 SG_ stringInitStatus_BMS29 : 49|2@0+ (1,0) [0|3] ""  BMS
 SG_ thermalEventTypeS_BMS29 : 46|1@0+ (1,0) [0|1] ""  BMS
 SG_ thermalEventStatus_BMS29 : 45|2@0+ (1,0) [0|2550] ""  BMS
 SG_ thermalFaultIndex_BMS29 : 43|3@0+ (1,0) [0|7] ""  BMS
 SG_ faultBitHVIL_BMS29 : 40|1@0+ (1,0) [0|1] ""  BMS
 SG_ linkVoltage_BMS29 : 23|16@0+ (0.02,0) [0|1200] "V"  BMS
 SG_ current_BMS29 : 7|16@0+ (0.1,-3200) [-3200|3353.5] "A"  BMS
 SG_ chargeState_BMS29 : 39|4@0+ (1,0) [0|15] ""  BMS
 SG_ stringState_BMS29 : 35|4@0+ (1,0) [0|0] ""  BMS

BA_DEF_ SG_  "GenSigSendType" ENUM  "Cyclic","OnWrite","OnWriteWithRepetition","OnChange","OnChangeWithRepetition","IfActive","IfActiveWithRepetition","NoSigSendType";
BA_DEF_ BO_  "GenMsgCycleTime" INT 0 0;
BA_DEF_ BO_  "GenMsgSendType" ENUM  "Cyclic","not_used","not_used","not_used","not_used","Cyclic","not_used","IfActive","NoMsgSendType";
BA_DEF_DEF_  "GenSigSendType" "Cyclic";
BA_DEF_DEF_  "GenMsgCycleTime" 0;
BA_DEF_DEF_  "GenMsgSendType" "NoMsgSendType";
BA_ "GenMsgCycleTime" BO_ 113 100;
BA_ "GenMsgCycleTime" BO_ 17 10;
BA_ "GenMsgCycleTime" BO_ 402 1000;
BA_ "GenMsgCycleTime" BO_ 386 1000;
BA_ "GenMsgCycleTime" BO_ 354 1000;
BA_ "GenMsgCycleTime" BO_ 338 1000;
BA_ "GenMsgCycleTime" BO_ 322 1000;
BA_ "GenMsgCycleTime" BO_ 210 100;
BA_ "GenMsgCycleTime" BO_ 194 10;
BA_ "GenMsgCycleTime" BO_ 162 100;
BA_ "GenMsgCycleTime" BO_ 178 100;
BA_ "GenMsgCycleTime" BO_ 146 100;
BA_ "GenMsgCycleTime" BO_ 130 100;
BA_ "GenMsgCycleTime" BO_ 98 100;
BA_ "GenMsgCycleTime" BO_ 34 100;
BA_ "GenMsgCycleTime" BO_ 2 10;
BA_ "GenMsgCycleTime" BO_ 82 100;
BA_ "GenMsgCycleTime" BO_ 50 1000;
BA_ "GenMsgCycleTime" BO_ 66 1000;
BA_ "GenMsgCycleTime" BO_ 114 100;
BA_ "GenMsgCycleTime" BO_ 18 10;
BA_ "GenMsgCycleTime" BO_ 403 1000;
BA_ "GenMsgCycleTime" BO_ 387 1000;
BA_ "GenMsgCycleTime" BO_ 355 1000;
BA_ "GenMsgCycleTime" BO_ 339 1000;
BA_ "GenMsgCycleTime" BO_ 323 1000;
BA_ "GenMsgCycleTime" BO_ 211 100;
BA_ "GenMsgCycleTime" BO_ 195 10;
BA_ "GenMsgCycleTime" BO_ 163 100;
BA_ "GenMsgCycleTime" BO_ 179 100;
BA_ "GenMsgCycleTime" BO_ 147 100;
BA_ "GenMsgCycleTime" BO_ 131 100;
BA_ "GenMsgCycleTime" BO_ 99 100;
BA_ "GenMsgCycleTime" BO_ 35 100;
BA_ "GenMsgCycleTime" BO_ 3 10;
BA_ "GenMsgCycleTime" BO_ 83 100;
BA_ "GenMsgCycleTime" BO_ 51 1000;
BA_ "GenMsgCycleTime" BO_ 67 1000;
BA_ "GenMsgCycleTime" BO_ 115 100;
BA_ "GenMsgCycleTime" BO_ 19 10;
BA_ "GenMsgCycleTime" BO_ 404 1000;
BA_ "GenMsgCycleTime" BO_ 388 1000;
BA_ "GenMsgCycleTime" BO_ 356 1000;
BA_ "GenMsgCycleTime" BO_ 340 1000;
BA_ "GenMsgCycleTime" BO_ 324 1000;
BA_ "GenMsgCycleTime" BO_ 212 100;
BA_ "GenMsgCycleTime" BO_ 196 10;
BA_ "GenMsgCycleTime" BO_ 164 100;
BA_ "GenMsgCycleTime" BO_ 180 100;
BA_ "GenMsgCycleTime" BO_ 148 100;
BA_ "GenMsgCycleTime" BO_ 132 100;
BA_ "GenMsgCycleTime" BO_ 100 100;
BA_ "GenMsgCycleTime" BO_ 36 100;
BA_ "GenMsgCycleTime" BO_ 4 10;
BA_ "GenMsgCycleTime" BO_ 84 100;
BA_ "GenMsgCycleTime" BO_ 52 1000;
BA_ "GenMsgCycleTime" BO_ 68 1000;
BA_ "GenMsgCycleTime" BO_ 116 100;
BA_ "GenMsgCycleTime" BO_ 20 10;
BA_ "GenMsgCycleTime" BO_ 405 1000;
BA_ "GenMsgCycleTime" BO_ 389 1000;
BA_ "GenMsgCycleTime" BO_ 357 1000;
BA_ "GenMsgCycleTime" BO_ 341 1000;
BA_ "GenMsgCycleTime" BO_ 325 1000;
BA_ "GenMsgCycleTime" BO_ 213 100;
BA_ "GenMsgCycleTime" BO_ 197 10;
BA_ "GenMsgCycleTime" BO_ 165 100;
BA_ "GenMsgCycleTime" BO_ 181 100;
BA_ "GenMsgCycleTime" BO_ 149 100;
BA_ "GenMsgCycleTime" BO_ 133 100;
BA_ "GenMsgCycleTime" BO_ 101 100;
BA_ "GenMsgCycleTime" BO_ 37 100;
BA_ "GenMsgCycleTime" BO_ 5 10;
BA_ "GenMsgCycleTime" BO_ 85 100;
BA_ "GenMsgCycleTime" BO_ 53 1000;
BA_ "GenMsgCycleTime" BO_ 69 1000;
BA_ "GenMsgCycleTime" BO_ 117 100;
BA_ "GenMsgCycleTime" BO_ 21 10;
BA_ "GenMsgCycleTime" BO_ 406 1000;
BA_ "GenMsgCycleTime" BO_ 390 1000;
BA_ "GenMsgCycleTime" BO_ 358 1000;
BA_ "GenMsgCycleTime" BO_ 342 1000;
BA_ "GenMsgCycleTime" BO_ 326 1000;
BA_ "GenMsgCycleTime" BO_ 214 100;
BA_ "GenMsgCycleTime" BO_ 198 10;
BA_ "GenMsgCycleTime" BO_ 166 100;
BA_ "GenMsgCycleTime" BO_ 182 100;
BA_ "GenMsgCycleTime" BO_ 150 100;
BA_ "GenMsgCycleTime" BO_ 134 100;
BA_ "GenMsgCycleTime" BO_ 102 100;
BA_ "GenMsgCycleTime" BO_ 38 100;
BA_ "GenMsgCycleTime" BO_ 6 10;
BA_ "GenMsgCycleTime" BO_ 86 100;
BA_ "GenMsgCycleTime" BO_ 54 1000;
BA_ "GenMsgCycleTime" BO_ 70 1000;
BA_ "GenMsgCycleTime" BO_ 118 100;
BA_ "GenMsgCycleTime" BO_ 22 10;
BA_ "GenMsgCycleTime" BO_ 407 1000;
BA_ "GenMsgCycleTime" BO_ 391 1000;
BA_ "GenMsgCycleTime" BO_ 359 1000;
BA_ "GenMsgCycleTime" BO_ 343 1000;
BA_ "GenMsgCycleTime" BO_ 327 1000;
BA_ "GenMsgCycleTime" BO_ 215 100;
BA_ "GenMsgCycleTime" BO_ 199 10;
BA_ "GenMsgCycleTime" BO_ 167 100;
BA_ "GenMsgCycleTime" BO_ 183 100;
BA_ "GenMsgCycleTime" BO_ 151 100;
BA_ "GenMsgCycleTime" BO_ 135 100;
BA_ "GenMsgCycleTime" BO_ 103 100;
BA_ "GenMsgCycleTime" BO_ 39 100;
BA_ "GenMsgCycleTime" BO_ 7 10;
BA_ "GenMsgCycleTime" BO_ 87 100;
BA_ "GenMsgCycleTime" BO_ 55 1000;
BA_ "GenMsgCycleTime" BO_ 71 1000;
BA_ "GenMsgCycleTime" BO_ 119 100;
BA_ "GenMsgCycleTime" BO_ 23 10;
VAL_ 113 dchgCurrentLimit_BMS05 65535 "SNA" ;
VAL_ 113 regenCurrentLimit_BMS05 65535 "SNA" ;
VAL_ 113 minStringVLimit_BMS05 65535 "SNA" ;
VAL_ 113 maxStringVLimit_BMS05 65535 "SNA" ;
VAL_ 17 stringInitStatus_BMS05 3 "SNA" 1 "STRING_READY" 0 "STRING_NOT_READY" ;
VAL_ 17 thermalEventStatus_BMS05 3 "SNA" 2 "WARN_2" 1 "WARN_1" 0 "NO WARN" ;
VAL_ 17 linkVoltage_BMS05 65535 "SNA" ;
VAL_ 17 current_BMS05 0 "SHORT_CIRCUIT" 65535 "SNA" ;
VAL_ 17 chargeState_BMS05 15 "CHARGESTATE_INVALID" 1 "CHARGESTATE_COMPLETE" 0 "CHARGESTATE_NOTCOMPLETE" ;
VAL_ 17 stringState_BMS05 6 "STATE_ESS_FAULT" 15 "STATE_INVALID" 5 "STATE_STRING_FAULT" 4 "STATE_LIMPHOME" 3 "STATE_ACCESSORY" 2 "STATE_CHARGE" 1 "STATE_DRIVE" 0 "STATE_STANDBY" ;
VAL_ 386 maxFluidPressureInlet_BMS09 255 "SNA" ;
VAL_ 354 obdOccurrence_BMS09 127 "SNA" ;
VAL_ 354 obdClearFaultMemory_BMS09 1 "Triggered" 0 "Not triggered" ;
VAL_ 354 obdDTCOdometer_BMS09 65535 "SNA" ;
VAL_ 354 obdDTCId_BMS09 255 "SNA" ;
VAL_ 338 maxSOCIndex_BMS09 65535 "SNA" ;
VAL_ 338 minSOCIndex_BMS09 65535 "SNA" ;
VAL_ 322 cusDschrgEnrgyLifeTime_BMS09 65535 "SNA" ;
VAL_ 322 cusChrgEnrgyLifeTime_BMS09 65535 "SNA" ;
VAL_ 210 stringShutdownTarget_BMS09 6 "STATE_ESS_FAULT" 15 "STATE_INVALID" 5 "STATE_STRING_FAULT" 4 "STATE_LIMPHOME" 3 "STATE_ACCESSORY" 2 "STATE_CHARGE" 1 "STATE_DRIVE" 0 "STATE_STANDBY" ;
VAL_ 210 stringShutdownTimer_BMS09 65535 "SNA" ;
VAL_ 194 cntrStatePrechg2_BMS09 3 "CTR_INVALID" 1 "CTR_ON" 0 "CTR_OFF" ;
VAL_ 194 cntrStatePrechg1_BMS09 3 "CTR_INVALID" 1 "CTR_ON" 0 "CTR_OFF" ;
VAL_ 194 cntrStatePos3_BMS09 3 "CTR_INVALID" 1 "CTR_ON" 0 "CTR_OFF" ;
VAL_ 194 cntrStatePos2_BMS09 3 "CTR_INVALID" 1 "CTR_ON" 0 "CTR_OFF" ;
VAL_ 194 cntrStatePos1_BMS09 3 "CTR_INVALID" 1 "CTR_ON" 0 "CTR_OFF" ;
VAL_ 194 cntrStateNeg3_BMS09 3 "CTR_INVALID" 1 "CTR_ON" 0 "CTR_OFF" ;
VAL_ 194 cntrStateNeg2_BMS09 3 "CTR_INVALID" 1 "CTR_ON" 0 "CTR_OFF" ;
VAL_ 194 cntrStateNeg1_BMS09 3 "CTR_INVALID" 1 "CTR_ON" 0 "CTR_OFF" ;
VAL_ 194 cntrWeldState_BMS09 15 "CTR_WELD_UNKNWON" 3 "CTR_NEG1_WELDED" 2 "CTR_POS1_WELDED" 0 "CTR_NOTWELDED" 1 "CTR_BOTH_WELDED" ;
VAL_ 194 cntrState_BMS09 15 "CTR_INVALID" 3 "CTR_STRING_OPENING" 2 "CTR_STRING_ON" 1 "CTR_STRING_PRECHARGE" 0 "CTR_STRING_OFF" ;
VAL_ 162 regenPowerPredShrt_BMS09 65535 "SNA" ;
VAL_ 162 regenPowerPredLong_BMS09 65535 "SNA" ;
VAL_ 162 dchgPowerPredShrt_BMS09 65535 "SNA" ;
VAL_ 162 dchgPowerPredLong_BMS09 65535 "SNA" ;
VAL_ 178 cusMaxCellVLimit_BMS09 65535 "SNA" ;
VAL_ 178 cusMinCellVLimit_BMS09 65535 "SNA" ;
VAL_ 146 dchgVoltagePredShrt_BMS09 65535 "SNA" ;
VAL_ 146 dchgVoltagePredLong_BMS09 65535 "SNA" ;
VAL_ 146 regenVoltagePredShrt_BMS09 65535 "SNA" ;
VAL_ 146 regenVoltagePredLong_BMS09 65535 "SNA" ;
VAL_ 130 regenCurrentPredShrt_BMS09 65535 "SNA" ;
VAL_ 130 regenCurrentPredLong_BMS09 65535 "SNA" ;
VAL_ 130 dchgCurrentPredShrt_BMS09 65535 "SNA" ;
VAL_ 130 dchgCurrentPredLong_BMS09 65535 "SNA" ;
VAL_ 98 maxDewPointTemperature_BMS09 255 "SNA" ;
VAL_ 98 meanModuleTemperature_BMS09 255 "SNA" ;
VAL_ 98 minBrickCapacity_BMS09 65535 "SNA" ;
VAL_ 98 maxModuleTempIndex_BMS09 255 "SNA" ;
VAL_ 98 minModuleTempIndex_BMS09 255 "SNA" ;
VAL_ 98 maxModuleTempString_BMS09 255 "SNA" ;
VAL_ 98 minModuleTempString_BMS09 255 "SNA" ;
VAL_ 34 brickOpenCircuitV_BMS09 65535 "SNA" ;
VAL_ 34 meanSOC_BMS09 65535 "SNA" ;
VAL_ 34 stringVoltage_BMS09 65535 "SNA" ;
VAL_ 34 chargerCurrentLimit_BMS09 65535 "SNA" ;
VAL_ 2 isolationRequest_BMS09_BMS 4 "ISOLATION_AUXWELD" 15 "ISOLATION_INVALID" 1 "ISOLATION_ACTIVE" 0 "ISOLATION_INACTIVE" ;
VAL_ 2 stringStateReq_BMS09_BMS 6 "STATE_ESS_FAULT" 15 "STATE_INVALID" 5 "STATE_STRING_FAULT" 4 "STATE_LIMPHOME" 3 "STATE_ACCESSORY" 2 "STATE_CHARGE" 1 "STATE_DRIVE" 0 "STATE_STANDBY" ;
VAL_ 2 sleepRequest_BMS09_BMS 15 "SLEEP_INVALID" 1 "SLEEP_ACTIVE" 0 "SLEEP_INACTIVE" ;
VAL_ 82 maxBrickVoltageIndex_BMS09 65535 "SNA" ;
VAL_ 82 minBrickVoltageIndex_BMS09 65535 "SNA" ;
VAL_ 82 minBrickVoltage_BMS09 65535 "SNA" ;
VAL_ 82 maxBrickVoltage_BMS09 65535 "SNA" ;
VAL_ 50 maxSOC_BMS09 65535 "SNA" ;
VAL_ 50 minSOC_BMS09 65535 "SNA" ;
VAL_ 50 isolationResInternal_BMS09 65535 "SNA" ;
VAL_ 50 isolationResExternal_BMS09 65535 "SNA" ;
VAL_ 66 dchgIntResistance_BMS09 65535 "SNA" ;
VAL_ 66 regenIntResistance_BMS09 65535 "SNA" ;
VAL_ 66 maxSOH_BMS09 255 "SNA" ;
VAL_ 66 minSOH_BMS09 255 "SNA" ;
VAL_ 66 energyAvailable_BMS09 65535 "SNA" ;
VAL_ 114 dchgCurrentLimit_BMS09 65535 "SNA" ;
VAL_ 114 regenCurrentLimit_BMS09 65535 "SNA" ;
VAL_ 114 minStringVLimit_BMS09 65535 "SNA" ;
VAL_ 114 maxStringVLimit_BMS09 65535 "SNA" ;
VAL_ 18 stringInitStatus_BMS09 3 "SNA" 1 "STRING_READY" 0 "STRING_NOT_READY" ;
VAL_ 18 thermalEventStatus_BMS09 3 "SNA" 2 "WARN_2" 1 "WARN_1" 0 "NO WARN" ;
VAL_ 18 linkVoltage_BMS09 65535 "SNA" ;
VAL_ 18 current_BMS09 0 "SHORT_CIRCUIT" 65535 "SNA" ;
VAL_ 18 chargeState_BMS09 15 "CHARGESTATE_INVALID" 1 "CHARGESTATE_COMPLETE" 0 "CHARGESTATE_NOTCOMPLETE" ;
VAL_ 18 stringState_BMS09 6 "STATE_ESS_FAULT" 15 "STATE_INVALID" 5 "STATE_STRING_FAULT" 4 "STATE_LIMPHOME" 3 "STATE_ACCESSORY" 2 "STATE_CHARGE" 1 "STATE_DRIVE" 0 "STATE_STANDBY" ;
VAL_ 387 maxFluidPressureInlet_BMS13 255 "SNA" ;
VAL_ 355 obdOccurrence_BMS13 127 "SNA" ;
VAL_ 355 obdClearFaultMemory_BMS13 1 "Triggered" 0 "Not triggered" ;
VAL_ 355 obdDTCOdometer_BMS13 65535 "SNA" ;
VAL_ 355 obdDTCId_BMS13 255 "SNA" ;
VAL_ 339 maxSOCIndex_BMS13 65535 "SNA" ;
VAL_ 339 minSOCIndex_BMS13 65535 "SNA" ;
VAL_ 323 cusDschrgEnrgyLifeTime_BMS13 65535 "SNA" ;
VAL_ 323 cusChrgEnrgyLifeTime_BMS13 65535 "SNA" ;
VAL_ 211 stringShutdownTarget_BMS13 6 "STATE_ESS_FAULT" 15 "STATE_INVALID" 5 "STATE_STRING_FAULT" 4 "STATE_LIMPHOME" 3 "STATE_ACCESSORY" 2 "STATE_CHARGE" 1 "STATE_DRIVE" 0 "STATE_STANDBY" ;
VAL_ 211 stringShutdownTimer_BMS13 65535 "SNA" ;
VAL_ 195 cntrStatePrechg2_BMS13 3 "CTR_INVALID" 1 "CTR_ON" 0 "CTR_OFF" ;
VAL_ 195 cntrStatePrechg1_BMS13 3 "CTR_INVALID" 1 "CTR_ON" 0 "CTR_OFF" ;
VAL_ 195 cntrStatePos3_BMS13 3 "CTR_INVALID" 1 "CTR_ON" 0 "CTR_OFF" ;
VAL_ 195 cntrStatePos2_BMS13 3 "CTR_INVALID" 1 "CTR_ON" 0 "CTR_OFF" ;
VAL_ 195 cntrStatePos1_BMS13 3 "CTR_INVALID" 1 "CTR_ON" 0 "CTR_OFF" ;
VAL_ 195 cntrStateNeg3_BMS13 3 "CTR_INVALID" 1 "CTR_ON" 0 "CTR_OFF" ;
VAL_ 195 cntrStateNeg2_BMS13 3 "CTR_INVALID" 1 "CTR_ON" 0 "CTR_OFF" ;
VAL_ 195 cntrStateNeg1_BMS13 3 "CTR_INVALID" 1 "CTR_ON" 0 "CTR_OFF" ;
VAL_ 195 cntrWeldState_BMS13 15 "CTR_WELD_UNKNWON" 3 "CTR_NEG1_WELDED" 2 "CTR_POS1_WELDED" 0 "CTR_NOTWELDED" 1 "CTR_BOTH_WELDED" ;
VAL_ 195 cntrState_BMS13 15 "CTR_INVALID" 3 "CTR_STRING_OPENING" 2 "CTR_STRING_ON" 1 "CTR_STRING_PRECHARGE" 0 "CTR_STRING_OFF" ;
VAL_ 163 regenPowerPredShrt_BMS13 65535 "SNA" ;
VAL_ 163 regenPowerPredLong_BMS13 65535 "SNA" ;
VAL_ 163 dchgPowerPredShrt_BMS13 65535 "SNA" ;
VAL_ 163 dchgPowerPredLong_BMS13 65535 "SNA" ;
VAL_ 179 cusMaxCellVLimit_BMS13 65535 "SNA" ;
VAL_ 179 cusMinCellVLimit_BMS13 65535 "SNA" ;
VAL_ 147 dchgVoltagePredShrt_BMS13 65535 "SNA" ;
VAL_ 147 dchgVoltagePredLong_BMS13 65535 "SNA" ;
VAL_ 147 regenVoltagePredShrt_BMS13 65535 "SNA" ;
VAL_ 147 regenVoltagePredLong_BMS13 65535 "SNA" ;
VAL_ 131 regenCurrentPredShrt_BMS13 65535 "SNA" ;
VAL_ 131 regenCurrentPredLong_BMS13 65535 "SNA" ;
VAL_ 131 dchgCurrentPredShrt_BMS13 65535 "SNA" ;
VAL_ 131 dchgCurrentPredLong_BMS13 65535 "SNA" ;
VAL_ 99 maxDewPointTemperature_BMS13 255 "SNA" ;
VAL_ 99 meanModuleTemperature_BMS13 255 "SNA" ;
VAL_ 99 minBrickCapacity_BMS13 65535 "SNA" ;
VAL_ 99 maxModuleTempIndex_BMS13 255 "SNA" ;
VAL_ 99 minModuleTempIndex_BMS13 255 "SNA" ;
VAL_ 99 maxModuleTempString_BMS13 255 "SNA" ;
VAL_ 99 minModuleTempString_BMS13 255 "SNA" ;
VAL_ 35 brickOpenCircuitV_BMS13 65535 "SNA" ;
VAL_ 35 meanSOC_BMS13 65535 "SNA" ;
VAL_ 35 stringVoltage_BMS13 65535 "SNA" ;
VAL_ 35 chargerCurrentLimit_BMS13 65535 "SNA" ;
VAL_ 3 isolationRequest_BMS13_BMS 4 "ISOLATION_AUXWELD" 15 "ISOLATION_INVALID" 1 "ISOLATION_ACTIVE" 0 "ISOLATION_INACTIVE" ;
VAL_ 3 stringStateReq_BMS13_BMS 6 "STATE_ESS_FAULT" 15 "STATE_INVALID" 5 "STATE_STRING_FAULT" 4 "STATE_LIMPHOME" 3 "STATE_ACCESSORY" 2 "STATE_CHARGE" 1 "STATE_DRIVE" 0 "STATE_STANDBY" ;
VAL_ 3 sleepRequest_BMS13_BMS 15 "SLEEP_INVALID" 1 "SLEEP_ACTIVE" 0 "SLEEP_INACTIVE" ;
VAL_ 83 maxBrickVoltageIndex_BMS13 65535 "SNA" ;
VAL_ 83 minBrickVoltageIndex_BMS13 65535 "SNA" ;
VAL_ 83 minBrickVoltage_BMS13 65535 "SNA" ;
VAL_ 83 maxBrickVoltage_BMS13 65535 "SNA" ;
VAL_ 51 maxSOC_BMS13 65535 "SNA" ;
VAL_ 51 minSOC_BMS13 65535 "SNA" ;
VAL_ 51 isolationResInternal_BMS13 65535 "SNA" ;
VAL_ 51 isolationResExternal_BMS13 65535 "SNA" ;
VAL_ 67 dchgIntResistance_BMS13 65535 "SNA" ;
VAL_ 67 regenIntResistance_BMS13 65535 "SNA" ;
VAL_ 67 maxSOH_BMS13 255 "SNA" ;
VAL_ 67 minSOH_BMS13 255 "SNA" ;
VAL_ 67 energyAvailable_BMS13 65535 "SNA" ;
VAL_ 115 dchgCurrentLimit_BMS13 65535 "SNA" ;
VAL_ 115 regenCurrentLimit_BMS13 65535 "SNA" ;
VAL_ 115 minStringVLimit_BMS13 65535 "SNA" ;
VAL_ 115 maxStringVLimit_BMS13 65535 "SNA" ;
VAL_ 19 stringInitStatus_BMS13 3 "SNA" 1 "STRING_READY" 0 "STRING_NOT_READY" ;
VAL_ 19 thermalEventStatus_BMS13 3 "SNA" 2 "WARN_2" 1 "WARN_1" 0 "NO WARN" ;
VAL_ 19 linkVoltage_BMS13 65535 "SNA" ;
VAL_ 19 current_BMS13 0 "SHORT_CIRCUIT" 65535 "SNA" ;
VAL_ 19 chargeState_BMS13 15 "CHARGESTATE_INVALID" 1 "CHARGESTATE_COMPLETE" 0 "CHARGESTATE_NOTCOMPLETE" ;
VAL_ 19 stringState_BMS13 6 "STATE_ESS_FAULT" 15 "STATE_INVALID" 5 "STATE_STRING_FAULT" 4 "STATE_LIMPHOME" 3 "STATE_ACCESSORY" 2 "STATE_CHARGE" 1 "STATE_DRIVE" 0 "STATE_STANDBY" ;
VAL_ 388 maxFluidPressureInlet_BMS17 255 "SNA" ;
VAL_ 356 obdOccurrence_BMS17 127 "SNA" ;
VAL_ 356 obdClearFaultMemory_BMS17 1 "Triggered" 0 "Not triggered" ;
VAL_ 356 obdDTCOdometer_BMS17 65535 "SNA" ;
VAL_ 356 obdDTCId_BMS17 255 "SNA" ;
VAL_ 340 maxSOCIndex_BMS17 65535 "SNA" ;
VAL_ 340 minSOCIndex_BMS17 65535 "SNA" ;
VAL_ 324 cusDschrgEnrgyLifeTime_BMS17 65535 "SNA" ;
VAL_ 324 cusChrgEnrgyLifeTime_BMS17 65535 "SNA" ;
VAL_ 212 stringShutdownTarget_BMS17 6 "STATE_ESS_FAULT" 15 "STATE_INVALID" 5 "STATE_STRING_FAULT" 4 "STATE_LIMPHOME" 3 "STATE_ACCESSORY" 2 "STATE_CHARGE" 1 "STATE_DRIVE" 0 "STATE_STANDBY" ;
VAL_ 212 stringShutdownTimer_BMS17 65535 "SNA" ;
VAL_ 196 cntrStatePrechg2_BMS17 3 "CTR_INVALID" 1 "CTR_ON" 0 "CTR_OFF" ;
VAL_ 196 cntrStatePrechg1_BMS17 3 "CTR_INVALID" 1 "CTR_ON" 0 "CTR_OFF" ;
VAL_ 196 cntrStatePos3_BMS17 3 "CTR_INVALID" 1 "CTR_ON" 0 "CTR_OFF" ;
VAL_ 196 cntrStatePos2_BMS17 3 "CTR_INVALID" 1 "CTR_ON" 0 "CTR_OFF" ;
VAL_ 196 cntrStatePos1_BMS17 3 "CTR_INVALID" 1 "CTR_ON" 0 "CTR_OFF" ;
VAL_ 196 cntrStateNeg3_BMS17 3 "CTR_INVALID" 1 "CTR_ON" 0 "CTR_OFF" ;
VAL_ 196 cntrStateNeg2_BMS17 3 "CTR_INVALID" 1 "CTR_ON" 0 "CTR_OFF" ;
VAL_ 196 cntrStateNeg1_BMS17 3 "CTR_INVALID" 1 "CTR_ON" 0 "CTR_OFF" ;
VAL_ 196 cntrWeldState_BMS17 15 "CTR_WELD_UNKNWON" 3 "CTR_NEG1_WELDED" 2 "CTR_POS1_WELDED" 0 "CTR_NOTWELDED" 1 "CTR_BOTH_WELDED" ;
VAL_ 196 cntrState_BMS17 15 "CTR_INVALID" 3 "CTR_STRING_OPENING" 2 "CTR_STRING_ON" 1 "CTR_STRING_PRECHARGE" 0 "CTR_STRING_OFF" ;
VAL_ 164 regenPowerPredShrt_BMS17 65535 "SNA" ;
VAL_ 164 regenPowerPredLong_BMS17 65535 "SNA" ;
VAL_ 164 dchgPowerPredShrt_BMS17 65535 "SNA" ;
VAL_ 164 dchgPowerPredLong_BMS17 65535 "SNA" ;
VAL_ 180 cusMaxCellVLimit_BMS17 65535 "SNA" ;
VAL_ 180 cusMinCellVLimit_BMS17 65535 "SNA" ;
VAL_ 148 dchgVoltagePredShrt_BMS17 65535 "SNA" ;
VAL_ 148 dchgVoltagePredLong_BMS17 65535 "SNA" ;
VAL_ 148 regenVoltagePredShrt_BMS17 65535 "SNA" ;
VAL_ 148 regenVoltagePredLong_BMS17 65535 "SNA" ;
VAL_ 132 regenCurrentPredShrt_BMS17 65535 "SNA" ;
VAL_ 132 regenCurrentPredLong_BMS17 65535 "SNA" ;
VAL_ 132 dchgCurrentPredShrt_BMS17 65535 "SNA" ;
VAL_ 132 dchgCurrentPredLong_BMS17 65535 "SNA" ;
VAL_ 100 maxDewPointTemperature_BMS17 255 "SNA" ;
VAL_ 100 meanModuleTemperature_BMS17 255 "SNA" ;
VAL_ 100 minBrickCapacity_BMS17 65535 "SNA" ;
VAL_ 100 maxModuleTempIndex_BMS17 255 "SNA" ;
VAL_ 100 minModuleTempIndex_BMS17 255 "SNA" ;
VAL_ 100 maxModuleTempString_BMS17 255 "SNA" ;
VAL_ 100 minModuleTempString_BMS17 255 "SNA" ;
VAL_ 36 brickOpenCircuitV_BMS17 65535 "SNA" ;
VAL_ 36 meanSOC_BMS17 65535 "SNA" ;
VAL_ 36 stringVoltage_BMS17 65535 "SNA" ;
VAL_ 36 chargerCurrentLimit_BMS17 65535 "SNA" ;
VAL_ 4 isolationRequest_BMS17_BMS 4 "ISOLATION_AUXWELD" 15 "ISOLATION_INVALID" 1 "ISOLATION_ACTIVE" 0 "ISOLATION_INACTIVE" ;
VAL_ 4 stringStateReq_BMS17_BMS 6 "STATE_ESS_FAULT" 15 "STATE_INVALID" 5 "STATE_STRING_FAULT" 4 "STATE_LIMPHOME" 3 "STATE_ACCESSORY" 2 "STATE_CHARGE" 1 "STATE_DRIVE" 0 "STATE_STANDBY" ;
VAL_ 4 sleepRequest_BMS17_BMS 15 "SLEEP_INVALID" 1 "SLEEP_ACTIVE" 0 "SLEEP_INACTIVE" ;
VAL_ 84 maxBrickVoltageIndex_BMS17 65535 "SNA" ;
VAL_ 84 minBrickVoltageIndex_BMS17 65535 "SNA" ;
VAL_ 84 minBrickVoltage_BMS17 65535 "SNA" ;
VAL_ 84 maxBrickVoltage_BMS17 65535 "SNA" ;
VAL_ 52 maxSOC_BMS17 65535 "SNA" ;
VAL_ 52 minSOC_BMS17 65535 "SNA" ;
VAL_ 52 isolationResInternal_BMS17 65535 "SNA" ;
VAL_ 52 isolationResExternal_BMS17 65535 "SNA" ;
VAL_ 68 dchgIntResistance_BMS17 65535 "SNA" ;
VAL_ 68 regenIntResistance_BMS17 65535 "SNA" ;
VAL_ 68 maxSOH_BMS17 255 "SNA" ;
VAL_ 68 minSOH_BMS17 255 "SNA" ;
VAL_ 68 energyAvailable_BMS17 65535 "SNA" ;
VAL_ 116 dchgCurrentLimit_BMS17 65535 "SNA" ;
VAL_ 116 regenCurrentLimit_BMS17 65535 "SNA" ;
VAL_ 116 minStringVLimit_BMS17 65535 "SNA" ;
VAL_ 116 maxStringVLimit_BMS17 65535 "SNA" ;
VAL_ 20 stringInitStatus_BMS17 3 "SNA" 1 "STRING_READY" 0 "STRING_NOT_READY" ;
VAL_ 20 thermalEventStatus_BMS17 3 "SNA" 2 "WARN_2" 1 "WARN_1" 0 "NO WARN" ;
VAL_ 20 linkVoltage_BMS17 65535 "SNA" ;
VAL_ 20 current_BMS17 0 "SHORT_CIRCUIT" 65535 "SNA" ;
VAL_ 20 chargeState_BMS17 15 "CHARGESTATE_INVALID" 1 "CHARGESTATE_COMPLETE" 0 "CHARGESTATE_NOTCOMPLETE" ;
VAL_ 20 stringState_BMS17 6 "STATE_ESS_FAULT" 15 "STATE_INVALID" 5 "STATE_STRING_FAULT" 4 "STATE_LIMPHOME" 3 "STATE_ACCESSORY" 2 "STATE_CHARGE" 1 "STATE_DRIVE" 0 "STATE_STANDBY" ;
VAL_ 389 maxFluidPressureInlet_BMS21 255 "SNA" ;
VAL_ 357 obdOccurrence_BMS21 127 "SNA" ;
VAL_ 357 obdClearFaultMemory_BMS21 1 "Triggered" 0 "Not triggered" ;
VAL_ 357 obdDTCOdometer_BMS21 65535 "SNA" ;
VAL_ 357 obdDTCId_BMS21 255 "SNA" ;
VAL_ 341 maxSOCIndex_BMS21 65535 "SNA" ;
VAL_ 341 minSOCIndex_BMS21 65535 "SNA" ;
VAL_ 325 cusDschrgEnrgyLifeTime_BMS21 65535 "SNA" ;
VAL_ 325 cusChrgEnrgyLifeTime_BMS21 65535 "SNA" ;
VAL_ 213 stringShutdownTarget_BMS21 6 "STATE_ESS_FAULT" 15 "STATE_INVALID" 5 "STATE_STRING_FAULT" 4 "STATE_LIMPHOME" 3 "STATE_ACCESSORY" 2 "STATE_CHARGE" 1 "STATE_DRIVE" 0 "STATE_STANDBY" ;
VAL_ 213 stringShutdownTimer_BMS21 65535 "SNA" ;
VAL_ 197 cntrStatePrechg2_BMS21 3 "CTR_INVALID" 1 "CTR_ON" 0 "CTR_OFF" ;
VAL_ 197 cntrStatePrechg1_BMS21 3 "CTR_INVALID" 1 "CTR_ON" 0 "CTR_OFF" ;
VAL_ 197 cntrStatePos3_BMS21 3 "CTR_INVALID" 1 "CTR_ON" 0 "CTR_OFF" ;
VAL_ 197 cntrStatePos2_BMS21 3 "CTR_INVALID" 1 "CTR_ON" 0 "CTR_OFF" ;
VAL_ 197 cntrStatePos1_BMS21 3 "CTR_INVALID" 1 "CTR_ON" 0 "CTR_OFF" ;
VAL_ 197 cntrStateNeg3_BMS21 3 "CTR_INVALID" 1 "CTR_ON" 0 "CTR_OFF" ;
VAL_ 197 cntrStateNeg2_BMS21 3 "CTR_INVALID" 1 "CTR_ON" 0 "CTR_OFF" ;
VAL_ 197 cntrStateNeg1_BMS21 3 "CTR_INVALID" 1 "CTR_ON" 0 "CTR_OFF" ;
VAL_ 197 cntrWeldState_BMS21 15 "CTR_WELD_UNKNWON" 3 "CTR_NEG1_WELDED" 2 "CTR_POS1_WELDED" 0 "CTR_NOTWELDED" 1 "CTR_BOTH_WELDED" ;
VAL_ 197 cntrState_BMS21 15 "CTR_INVALID" 3 "CTR_STRING_OPENING" 2 "CTR_STRING_ON" 1 "CTR_STRING_PRECHARGE" 0 "CTR_STRING_OFF" ;
VAL_ 165 regenPowerPredShrt_BMS21 65535 "SNA" ;
VAL_ 165 regenPowerPredLong_BMS21 65535 "SNA" ;
VAL_ 165 dchgPowerPredShrt_BMS21 65535 "SNA" ;
VAL_ 165 dchgPowerPredLong_BMS21 65535 "SNA" ;
VAL_ 181 cusMaxCellVLimit_BMS21 65535 "SNA" ;
VAL_ 181 cusMinCellVLimit_BMS21 65535 "SNA" ;
VAL_ 149 dchgVoltagePredShrt_BMS21 65535 "SNA" ;
VAL_ 149 dchgVoltagePredLong_BMS21 65535 "SNA" ;
VAL_ 149 regenVoltagePredShrt_BMS21 65535 "SNA" ;
VAL_ 149 regenVoltagePredLong_BMS21 65535 "SNA" ;
VAL_ 133 regenCurrentPredShrt_BMS21 65535 "SNA" ;
VAL_ 133 regenCurrentPredLong_BMS21 65535 "SNA" ;
VAL_ 133 dchgCurrentPredShrt_BMS21 65535 "SNA" ;
VAL_ 133 dchgCurrentPredLong_BMS21 65535 "SNA" ;
VAL_ 101 maxDewPointTemperature_BMS21 255 "SNA" ;
VAL_ 101 meanModuleTemperature_BMS21 255 "SNA" ;
VAL_ 101 minBrickCapacity_BMS21 65535 "SNA" ;
VAL_ 101 maxModuleTempIndex_BMS21 255 "SNA" ;
VAL_ 101 minModuleTempIndex_BMS21 255 "SNA" ;
VAL_ 101 maxModuleTempString_BMS21 255 "SNA" ;
VAL_ 101 minModuleTempString_BMS21 255 "SNA" ;
VAL_ 37 brickOpenCircuitV_BMS21 65535 "SNA" ;
VAL_ 37 meanSOC_BMS21 65535 "SNA" ;
VAL_ 37 stringVoltage_BMS21 65535 "SNA" ;
VAL_ 37 chargerCurrentLimit_BMS21 65535 "SNA" ;
VAL_ 5 isolationRequest_BMS21_BMS 4 "ISOLATION_AUXWELD" 15 "ISOLATION_INVALID" 1 "ISOLATION_ACTIVE" 0 "ISOLATION_INACTIVE" ;
VAL_ 5 stringStateReq_BMS21_BMS 6 "STATE_ESS_FAULT" 15 "STATE_INVALID" 5 "STATE_STRING_FAULT" 4 "STATE_LIMPHOME" 3 "STATE_ACCESSORY" 2 "STATE_CHARGE" 1 "STATE_DRIVE" 0 "STATE_STANDBY" ;
VAL_ 5 sleepRequest_BMS21_BMS 15 "SLEEP_INVALID" 1 "SLEEP_ACTIVE" 0 "SLEEP_INACTIVE" ;
VAL_ 85 maxBrickVoltageIndex_BMS21 65535 "SNA" ;
VAL_ 85 minBrickVoltageIndex_BMS21 65535 "SNA" ;
VAL_ 85 minBrickVoltage_BMS21 65535 "SNA" ;
VAL_ 85 maxBrickVoltage_BMS21 65535 "SNA" ;
VAL_ 53 maxSOC_BMS21 65535 "SNA" ;
VAL_ 53 minSOC_BMS21 65535 "SNA" ;
VAL_ 53 isolationResInternal_BMS21 65535 "SNA" ;
VAL_ 53 isolationResExternal_BMS21 65535 "SNA" ;
VAL_ 69 dchgIntResistance_BMS21 65535 "SNA" ;
VAL_ 69 regenIntResistance_BMS21 65535 "SNA" ;
VAL_ 69 maxSOH_BMS21 255 "SNA" ;
VAL_ 69 minSOH_BMS21 255 "SNA" ;
VAL_ 69 energyAvailable_BMS21 65535 "SNA" ;
VAL_ 117 dchgCurrentLimit_BMS21 65535 "SNA" ;
VAL_ 117 regenCurrentLimit_BMS21 65535 "SNA" ;
VAL_ 117 minStringVLimit_BMS21 65535 "SNA" ;
VAL_ 117 maxStringVLimit_BMS21 65535 "SNA" ;
VAL_ 21 stringInitStatus_BMS21 3 "SNA" 1 "STRING_READY" 0 "STRING_NOT_READY" ;
VAL_ 21 thermalEventStatus_BMS21 3 "SNA" 2 "WARN_2" 1 "WARN_1" 0 "NO WARN" ;
VAL_ 21 linkVoltage_BMS21 65535 "SNA" ;
VAL_ 21 current_BMS21 0 "SHORT_CIRCUIT" 65535 "SNA" ;
VAL_ 21 chargeState_BMS21 15 "CHARGESTATE_INVALID" 1 "CHARGESTATE_COMPLETE" 0 "CHARGESTATE_NOTCOMPLETE" ;
VAL_ 21 stringState_BMS21 6 "STATE_ESS_FAULT" 15 "STATE_INVALID" 5 "STATE_STRING_FAULT" 4 "STATE_LIMPHOME" 3 "STATE_ACCESSORY" 2 "STATE_CHARGE" 1 "STATE_DRIVE" 0 "STATE_STANDBY" ;
VAL_ 390 maxFluidPressureInlet_BMS25 255 "SNA" ;
VAL_ 358 obdOccurrence_BMS25 127 "SNA" ;
VAL_ 358 obdClearFaultMemory_BMS25 1 "Triggered" 0 "Not triggered" ;
VAL_ 358 obdDTCOdometer_BMS25 65535 "SNA" ;
VAL_ 358 obdDTCId_BMS25 255 "SNA" ;
VAL_ 342 maxSOCIndex_BMS25 65535 "SNA" ;
VAL_ 342 minSOCIndex_BMS25 65535 "SNA" ;
VAL_ 326 cusDschrgEnrgyLifeTime_BMS25 65535 "SNA" ;
VAL_ 326 cusChrgEnrgyLifeTime_BMS25 65535 "SNA" ;
VAL_ 214 stringShutdownTarget_BMS25 6 "STATE_ESS_FAULT" 15 "STATE_INVALID" 5 "STATE_STRING_FAULT" 4 "STATE_LIMPHOME" 3 "STATE_ACCESSORY" 2 "STATE_CHARGE" 1 "STATE_DRIVE" 0 "STATE_STANDBY" ;
VAL_ 214 stringShutdownTimer_BMS25 65535 "SNA" ;
VAL_ 198 cntrStatePrechg2_BMS25 3 "CTR_INVALID" 1 "CTR_ON" 0 "CTR_OFF" ;
VAL_ 198 cntrStatePrechg1_BMS25 3 "CTR_INVALID" 1 "CTR_ON" 0 "CTR_OFF" ;
VAL_ 198 cntrStatePos3_BMS25 3 "CTR_INVALID" 1 "CTR_ON" 0 "CTR_OFF" ;
VAL_ 198 cntrStatePos2_BMS25 3 "CTR_INVALID" 1 "CTR_ON" 0 "CTR_OFF" ;
VAL_ 198 cntrStatePos1_BMS25 3 "CTR_INVALID" 1 "CTR_ON" 0 "CTR_OFF" ;
VAL_ 198 cntrStateNeg3_BMS25 3 "CTR_INVALID" 1 "CTR_ON" 0 "CTR_OFF" ;
VAL_ 198 cntrStateNeg2_BMS25 3 "CTR_INVALID" 1 "CTR_ON" 0 "CTR_OFF" ;
VAL_ 198 cntrStateNeg1_BMS25 3 "CTR_INVALID" 1 "CTR_ON" 0 "CTR_OFF" ;
VAL_ 198 cntrWeldState_BMS25 15 "CTR_WELD_UNKNWON" 3 "CTR_NEG1_WELDED" 2 "CTR_POS1_WELDED" 0 "CTR_NOTWELDED" 1 "CTR_BOTH_WELDED" ;
VAL_ 198 cntrState_BMS25 15 "CTR_INVALID" 3 "CTR_STRING_OPENING" 2 "CTR_STRING_ON" 1 "CTR_STRING_PRECHARGE" 0 "CTR_STRING_OFF" ;
VAL_ 166 regenPowerPredShrt_BMS25 65535 "SNA" ;
VAL_ 166 regenPowerPredLong_BMS25 65535 "SNA" ;
VAL_ 166 dchgPowerPredShrt_BMS25 65535 "SNA" ;
VAL_ 166 dchgPowerPredLong_BMS25 65535 "SNA" ;
VAL_ 182 cusMaxCellVLimit_BMS25 65535 "SNA" ;
VAL_ 182 cusMinCellVLimit_BMS25 65535 "SNA" ;
VAL_ 150 dchgVoltagePredShrt_BMS25 65535 "SNA" ;
VAL_ 150 dchgVoltagePredLong_BMS25 65535 "SNA" ;
VAL_ 150 regenVoltagePredShrt_BMS25 65535 "SNA" ;
VAL_ 150 regenVoltagePredLong_BMS25 65535 "SNA" ;
VAL_ 134 regenCurrentPredShrt_BMS25 65535 "SNA" ;
VAL_ 134 regenCurrentPredLong_BMS25 65535 "SNA" ;
VAL_ 134 dchgCurrentPredShrt_BMS25 65535 "SNA" ;
VAL_ 134 dchgCurrentPredLong_BMS25 65535 "SNA" ;
VAL_ 102 maxDewPointTemperature_BMS25 255 "SNA" ;
VAL_ 102 meanModuleTemperature_BMS25 255 "SNA" ;
VAL_ 102 minBrickCapacity_BMS25 65535 "SNA" ;
VAL_ 102 maxModuleTempIndex_BMS25 255 "SNA" ;
VAL_ 102 minModuleTempIndex_BMS25 255 "SNA" ;
VAL_ 102 maxModuleTempString_BMS25 255 "SNA" ;
VAL_ 102 minModuleTempString_BMS25 255 "SNA" ;
VAL_ 38 brickOpenCircuitV_BMS25 65535 "SNA" ;
VAL_ 38 meanSOC_BMS25 65535 "SNA" ;
VAL_ 38 stringVoltage_BMS25 65535 "SNA" ;
VAL_ 38 chargerCurrentLimit_BMS25 65535 "SNA" ;
VAL_ 6 isolationRequest_BMS25_BMS 4 "ISOLATION_AUXWELD" 15 "ISOLATION_INVALID" 1 "ISOLATION_ACTIVE" 0 "ISOLATION_INACTIVE" ;
VAL_ 6 stringStateReq_BMS25_BMS 6 "STATE_ESS_FAULT" 15 "STATE_INVALID" 5 "STATE_STRING_FAULT" 4 "STATE_LIMPHOME" 3 "STATE_ACCESSORY" 2 "STATE_CHARGE" 1 "STATE_DRIVE" 0 "STATE_STANDBY" ;
VAL_ 6 sleepRequest_BMS25_BMS 15 "SLEEP_INVALID" 1 "SLEEP_ACTIVE" 0 "SLEEP_INACTIVE" ;
VAL_ 86 maxBrickVoltageIndex_BMS25 65535 "SNA" ;
VAL_ 86 minBrickVoltageIndex_BMS25 65535 "SNA" ;
VAL_ 86 minBrickVoltage_BMS25 65535 "SNA" ;
VAL_ 86 maxBrickVoltage_BMS25 65535 "SNA" ;
VAL_ 54 maxSOC_BMS25 65535 "SNA" ;
VAL_ 54 minSOC_BMS25 65535 "SNA" ;
VAL_ 54 isolationResInternal_BMS25 65535 "SNA" ;
VAL_ 54 isolationResExternal_BMS25 65535 "SNA" ;
VAL_ 70 dchgIntResistance_BMS25 65535 "SNA" ;
VAL_ 70 regenIntResistance_BMS25 65535 "SNA" ;
VAL_ 70 maxSOH_BMS25 255 "SNA" ;
VAL_ 70 minSOH_BMS25 255 "SNA" ;
VAL_ 70 energyAvailable_BMS25 65535 "SNA" ;
VAL_ 118 dchgCurrentLimit_BMS25 65535 "SNA" ;
VAL_ 118 regenCurrentLimit_BMS25 65535 "SNA" ;
VAL_ 118 minStringVLimit_BMS25 65535 "SNA" ;
VAL_ 118 maxStringVLimit_BMS25 65535 "SNA" ;
VAL_ 22 stringInitStatus_BMS25 3 "SNA" 1 "STRING_READY" 0 "STRING_NOT_READY" ;
VAL_ 22 thermalEventStatus_BMS25 3 "SNA" 2 "WARN_2" 1 "WARN_1" 0 "NO WARN" ;
VAL_ 22 linkVoltage_BMS25 65535 "SNA" ;
VAL_ 22 current_BMS25 0 "SHORT_CIRCUIT" 65535 "SNA" ;
VAL_ 22 chargeState_BMS25 15 "CHARGESTATE_INVALID" 1 "CHARGESTATE_COMPLETE" 0 "CHARGESTATE_NOTCOMPLETE" ;
VAL_ 22 stringState_BMS25 6 "STATE_ESS_FAULT" 15 "STATE_INVALID" 5 "STATE_STRING_FAULT" 4 "STATE_LIMPHOME" 3 "STATE_ACCESSORY" 2 "STATE_CHARGE" 1 "STATE_DRIVE" 0 "STATE_STANDBY" ;
VAL_ 391 maxFluidPressureInlet_BMS29 255 "SNA" ;
VAL_ 359 obdOccurrence_BMS29 127 "SNA" ;
VAL_ 359 obdClearFaultMemory_BMS29 1 "Triggered" 0 "Not triggered" ;
VAL_ 359 obdDTCOdometer_BMS29 65535 "SNA" ;
VAL_ 359 obdDTCId_BMS29 255 "SNA" ;
VAL_ 343 maxSOCIndex_BMS29 65535 "SNA" ;
VAL_ 343 minSOCIndex_BMS29 65535 "SNA" ;
VAL_ 327 cusDschrgEnrgyLifeTime_BMS29 65535 "SNA" ;
VAL_ 327 cusChrgEnrgyLifeTime_BMS29 65535 "SNA" ;
VAL_ 215 stringShutdownTarget_BMS29 6 "STATE_ESS_FAULT" 15 "STATE_INVALID" 5 "STATE_STRING_FAULT" 4 "STATE_LIMPHOME" 3 "STATE_ACCESSORY" 2 "STATE_CHARGE" 1 "STATE_DRIVE" 0 "STATE_STANDBY" ;
VAL_ 215 stringShutdownTimer_BMS29 65535 "SNA" ;
VAL_ 199 cntrStatePrechg2_BMS29 3 "CTR_INVALID" 1 "CTR_ON" 0 "CTR_OFF" ;
VAL_ 199 cntrStatePrechg1_BMS29 3 "CTR_INVALID" 1 "CTR_ON" 0 "CTR_OFF" ;
VAL_ 199 cntrStatePos3_BMS29 3 "CTR_INVALID" 1 "CTR_ON" 0 "CTR_OFF" ;
VAL_ 199 cntrStatePos2_BMS29 3 "CTR_INVALID" 1 "CTR_ON" 0 "CTR_OFF" ;
VAL_ 199 cntrStatePos1_BMS29 3 "CTR_INVALID" 1 "CTR_ON" 0 "CTR_OFF" ;
VAL_ 199 cntrStateNeg3_BMS29 3 "CTR_INVALID" 1 "CTR_ON" 0 "CTR_OFF" ;
VAL_ 199 cntrStateNeg2_BMS29 3 "CTR_INVALID" 1 "CTR_ON" 0 "CTR_OFF" ;
VAL_ 199 cntrStateNeg1_BMS29 3 "CTR_INVALID" 1 "CTR_ON" 0 "CTR_OFF" ;
VAL_ 199 cntrWeldState_BMS29 15 "CTR_WELD_UNKNWON" 3 "CTR_NEG1_WELDED" 2 "CTR_POS1_WELDED" 0 "CTR_NOTWELDED" 1 "CTR_BOTH_WELDED" ;
VAL_ 199 cntrState_BMS29 15 "CTR_INVALID" 3 "CTR_STRING_OPENING" 2 "CTR_STRING_ON" 1 "CTR_STRING_PRECHARGE" 0 "CTR_STRING_OFF" ;
VAL_ 167 regenPowerPredShrt_BMS29 65535 "SNA" ;
VAL_ 167 regenPowerPredLong_BMS29 65535 "SNA" ;
VAL_ 167 dchgPowerPredShrt_BMS29 65535 "SNA" ;
VAL_ 167 dchgPowerPredLong_BMS29 65535 "SNA" ;
VAL_ 183 cusMaxCellVLimit_BMS29 65535 "SNA" ;
VAL_ 183 cusMinCellVLimit_BMS29 65535 "SNA" ;
VAL_ 151 dchgVoltagePredShrt_BMS29 65535 "SNA" ;
VAL_ 151 dchgVoltagePredLong_BMS29 65535 "SNA" ;
VAL_ 151 regenVoltagePredShrt_BMS29 65535 "SNA" ;
VAL_ 151 regenVoltagePredLong_BMS29 65535 "SNA" ;
VAL_ 135 regenCurrentPredShrt_BMS29 65535 "SNA" ;
VAL_ 135 regenCurrentPredLong_BMS29 65535 "SNA" ;
VAL_ 135 dchgCurrentPredShrt_BMS29 65535 "SNA" ;
VAL_ 135 dchgCurrentPredLong_BMS29 65535 "SNA" ;
VAL_ 103 maxDewPointTemperature_BMS29 255 "SNA" ;
VAL_ 103 meanModuleTemperature_BMS29 255 "SNA" ;
VAL_ 103 minBrickCapacity_BMS29 65535 "SNA" ;
VAL_ 103 maxModuleTempIndex_BMS29 255 "SNA" ;
VAL_ 103 minModuleTempIndex_BMS29 255 "SNA" ;
VAL_ 103 maxModuleTempString_BMS29 255 "SNA" ;
VAL_ 103 minModuleTempString_BMS29 255 "SNA" ;
VAL_ 39 brickOpenCircuitV_BMS29 65535 "SNA" ;
VAL_ 39 meanSOC_BMS29 65535 "SNA" ;
VAL_ 39 stringVoltage_BMS29 65535 "SNA" ;
VAL_ 39 chargerCurrentLimit_BMS29 65535 "SNA" ;
VAL_ 7 isolationRequest_BMS29_BMS 4 "ISOLATION_AUXWELD" 15 "ISOLATION_INVALID" 1 "ISOLATION_ACTIVE" 0 "ISOLATION_INACTIVE" ;
VAL_ 7 stringStateReq_BMS29_BMS 6 "STATE_ESS_FAULT" 15 "STATE_INVALID" 5 "STATE_STRING_FAULT" 4 "STATE_LIMPHOME" 3 "STATE_ACCESSORY" 2 "STATE_CHARGE" 1 "STATE_DRIVE" 0 "STATE_STANDBY" ;
VAL_ 7 sleepRequest_BMS29_BMS 15 "SLEEP_INVALID" 1 "SLEEP_ACTIVE" 0 "SLEEP_INACTIVE" ;
VAL_ 87 maxBrickVoltageIndex_BMS29 65535 "SNA" ;
VAL_ 87 minBrickVoltageIndex_BMS29 65535 "SNA" ;
VAL_ 87 minBrickVoltage_BMS29 65535 "SNA" ;
VAL_ 87 maxBrickVoltage_BMS29 65535 "SNA" ;
VAL_ 55 maxSOC_BMS29 65535 "SNA" ;
VAL_ 55 minSOC_BMS29 65535 "SNA" ;
VAL_ 55 isolationResInternal_BMS29 65535 "SNA" ;
VAL_ 55 isolationResExternal_BMS29 65535 "SNA" ;
VAL_ 71 dchgIntResistance_BMS29 65535 "SNA" ;
VAL_ 71 regenIntResistance_BMS29 65535 "SNA" ;
VAL_ 71 maxSOH_BMS29 255 "SNA" ;
VAL_ 71 minSOH_BMS29 255 "SNA" ;
VAL_ 71 energyAvailable_BMS29 65535 "SNA" ;
VAL_ 119 dchgCurrentLimit_BMS29 65535 "SNA" ;
VAL_ 119 regenCurrentLimit_BMS29 65535 "SNA" ;
VAL_ 119 minStringVLimit_BMS29 65535 "SNA" ;
VAL_ 119 maxStringVLimit_BMS29 65535 "SNA" ;
VAL_ 23 stringInitStatus_BMS29 3 "SNA" 1 "STRING_READY" 0 "STRING_NOT_READY" ;
VAL_ 23 thermalEventStatus_BMS29 3 "SNA" 2 "WARN_2" 1 "WARN_1" 0 "NO WARN" ;
VAL_ 23 linkVoltage_BMS29 65535 "SNA" ;
VAL_ 23 current_BMS29 0 "SHORT_CIRCUIT" 65535 "SNA" ;
VAL_ 23 chargeState_BMS29 15 "CHARGESTATE_INVALID" 1 "CHARGESTATE_COMPLETE" 0 "CHARGESTATE_NOTCOMPLETE" ;
VAL_ 23 stringState_BMS29 6 "STATE_ESS_FAULT" 15 "STATE_INVALID" 5 "STATE_STRING_FAULT" 4 "STATE_LIMPHOME" 3 "STATE_ACCESSORY" 2 "STATE_CHARGE" 1 "STATE_DRIVE" 0 "STATE_STANDBY" ;
